VERSION "FL_CH_CANFD"

NS_ :

BS_:

BU_: ACU ADCC APA EGS EPS ESP FLZCU ONEBOX RXCU

BO_ 555 ONEBOX_3: 48 ESP
 SG_ ONEBOX_3_CRC1 : 7|8@0+ (1,0) [0|255] "" RXCU
 SG_ ONEBOX_3_RollgCntr1 : 11|4@0+ (1,0) [0|14] "" RXCU
 SG_ ONEBOX_3_Resd1 : 15|4@0+ (1,0) [0|15] "" RXCU
 SG_ ONEBOX_3_AVHSts : 17|2@0+ (1,0) [0|3] "" RXCU
 SG_ VehicleStandstill : 19|2@0+ (1,0) [0|3] "" RXCU
 SG_ NoBrakeForce : 22|1@0+ (1,0) [0|1] "" RXCU
 SG_ ONEBOX_3_AVHFailSts : 23|1@0+ (1,0) [0|1] "" RXCU
 SG_ Reserved_EDCActive : 24|1@0+ (1,0) [0|1] "" RXCU
 SG_ ECDTempOff : 25|1@0+ (1,0) [0|1] "" RXCU
 SG_ DCFail : 26|1@0+ (1,0) [0|1] "" RXCU
 SG_ CDDActive : 27|1@0+ (1,0) [0|1] "" RXCU
 SG_ CDDAvailable : 28|1@0+ (1,0) [0|1] "" RXCU
 SG_ Reserved_ESPLampInformation : 43|1@0+ (1,0) [0|1] "" RXCU
 SG_ TorqueMaxLimt : 55|8@0+ (16,0) [0|4064] "NM" RXCU
 SG_ ClutchOpenRequest : 57|2@0+ (1,0) [0|3] "" RXCU
 SG_ QDCACC : 63|2@0+ (1,0) [0|3] "" RXCU
 SG_ ONEBOX_3_CRC2 : 71|8@0+ (1,0) [0|255] "" RXCU
 SG_ ONEBOX_3_RollgCntr2 : 75|4@0+ (1,0) [0|14] "" RXCU
 SG_ ONEBOX_3_Resd2 : 79|4@0+ (1,0) [0|15] "" RXCU
 SG_ ONEBOX_3_WheelBrakeForce : 87|16@0+ (8,-250000) [-250000|250000] "N" RXCU
 SG_ TorqueIncreaseReqRA : 103|16@0+ (1,-32768) [-32768|32767] "NM" RXCU
 SG_ TorqueReductReqRA : 119|16@0+ (1,-32768) [-32768|32767] "NM" RXCU
 SG_ ONEBOX_3_CRC3 : 135|8@0+ (1,0) [0|255] "" RXCU
 SG_ ONEBOX_3_RollgCntr3 : 139|4@0+ (1,0) [0|14] "" RXCU
 SG_ ONEBOX_3_Resd3 : 143|4@0+ (1,0) [0|15] "" RXCU
 SG_ TorqueIncreaseReqFA : 151|16@0+ (1,-32768) [-32768|32767] "NM" RXCU
 SG_ TorqueReductReqFAFsat : 167|16@0+ (1,-32768) [-32768|32767] "NM" RXCU
 SG_ ONEBOX_3_CRC4 : 199|8@0+ (1,0) [0|255] "" RXCU
 SG_ ONEBOX_3_RollgCntr4 : 203|4@0+ (1,0) [0|14] "" RXCU
 SG_ ONEBOX_3_Resd4 : 207|4@0+ (1,0) [0|15] "" RXCU
 SG_ TorqueIncreaseReqRAValidData : 208|1@0+ (1,0) [0|1] "" RXCU
 SG_ TorqueReductReqRAValidData : 209|1@0+ (1,0) [0|1] "" RXCU
 SG_ TorqueIncreaseReqFAValidData : 210|1@0+ (1,0) [0|1] "" RXCU
 SG_ TorqueReductReqFAFastValidData : 211|1@0+ (1,0) [0|1] "" RXCU
 SG_ ESP_Park_CurrentSystemStatus : 215|3@0+ (1,0) [0|7] "" RXCU
 SG_ ESP_Pilot_CurrentSystemStatus : 218|3@0+ (1,0) [0|7] "" RXCU
 SG_ PlungerPressureValidData_22Bh : 220|1@0+ (1,0) [0|1] "" RXCU
 SG_ IPB_InputRodStrokeStatus_22Bh : 221|1@0+ (1,0) [0|1] "" RXCU
 SG_ SCMActive : 222|1@0+ (1,0) [0|1] "" RXCU
 SG_ SCMAvalable : 223|1@0+ (1,0) [0|1] "" RXCU
 SG_ IPB_PlungerPressure_22Bh : 231|10@0+ (1,0) [0|1022] "Bar" RXCU
 SG_ IPB_InputRodStroke_22Bh : 237|10@0+ (0.05,-5) [-5|46.15] "mm" RXCU
 SG_ BrakePedalPressStsValidData : 240|1@0+ (1,0) [0|1] "" RXCU
 SG_ DTCActive : 241|1@0+ (1,0) [0|1] "" RXCU
 SG_ DTCAvailable : 242|1@0+ (1,0) [0|1] "" RXCU
 SG_ DTC_Intervention : 243|1@0+ (1,0) [0|1] "" RXCU
 SG_ BrakePedalPressSts : 255|2@0+ (1,0) [0|3] "" RXCU
 SG_ ONEBOX_3_CRC5 : 263|8@0+ (1,0) [0|255] "" RXCU
 SG_ ONEBOX_3_RollgCntr5 : 267|4@0+ (1,0) [0|14] "" RXCU
 SG_ ONEBOX_3_Resd5 : 271|4@0+ (1,0) [0|15] "" RXCU
 SG_ ONEBOX_CRC6_22Bh : 327|8@0+ (1,0) [0|255] "" RXCU
 SG_ ONEBOX_RollgCntr6_22Bh : 331|4@0+ (1,0) [0|14] "" RXCU
 SG_ ONEBOX_Resd6_22Bh : 335|4@0+ (1,0) [0|15] "" RXCU

BO_ 571 FLZCU_1: 8 FLZCU
 SG_ DrvDoorSts_23Bh : 23|2@0+ (1,0) [0|3] "" RXCU
 SG_ DrvSeatBeltSW_23Bh : 31|1@0+ (1,0) [0|1] "" RXCU

BO_ 572 ONEBOX_7: 48 ESP
 SG_ ONEBOX_7_CRC1 : 7|8@0+ (1,0) [0|255] "" RXCU
 SG_ ONEBOX_7_RollgCntr1 : 11|4@0+ (1,0) [0|14] "" RXCU
 SG_ ONEBOX_7_Resd1 : 15|4@0+ (1,0) [0|15] "" RXCU
 SG_ ONEBOX_7_Crossaxis_TqtTrq : 23|16@0+ (1,-32768) [-32768|32767] "Nm" RXCU
 SG_ ONEBOX_7_iCCO_TqtTrq : 39|16@0+ (1,-32768) [-32768|32767] "Nm" RXCU
 SG_ ONEBOX_7_TAB_Active : 51|2@0+ (1,0) [0|3] "" RXCU
 SG_ ONEBOX_7_iTASDangerQuit : 52|1@0+ (1,0) [0|1] "" RXCU
 SG_ ONEBOX_7_RearWheelDirReq : 54|2@0+ (1,0) [0|3] "" RXCU
 SG_ ONEBOX_7_iTASAvailable : 55|1@0+ (1,0) [0|1] "" RXCU
 SG_ ONEBOX_7_iTASEnable : 56|1@0+ (1,0) [0|1] "" RXCU
 SG_ ONEBOX_7_iTASBMsr_FA : 57|1@0+ (1,0) [0|1] "" RXCU
 SG_ ONEBOX_7_iTASBMsr_RA : 58|1@0+ (1,0) [0|1] "" RXCU
 SG_ ONEBOX_7_BSW_Active : 60|2@0+ (1,0) [0|3] "" RXCU
 SG_ ONEBOX_7_iTASStuckDetected : 61|1@0+ (1,0) [0|1] "" RXCU
 SG_ ONEBOX_7_iTASTDiscHigh : 62|1@0+ (1,0) [0|1] "" RXCU
 SG_ ONEOBX_7_iTASAchMaxActTime : 63|1@0+ (1,0) [0|1] "" RXCU
 SG_ ONEBOX_7_CRC2 : 71|8@0+ (1,0) [0|255] "" RXCU
 SG_ ONEBOX_7_RollgCntr2 : 75|4@0+ (1,0) [0|14] "" RXCU
 SG_ ONEBOX_7_Resd2 : 79|4@0+ (1,0) [0|15] "" RXCU
 SG_ ONEBOX_7_iTASTorqueInc_FA : 87|16@0+ (1,-30000) [-30000|30000] "Nm" RXCU
 SG_ ONEBOX_7_DRIFTModeSts : 97|2@0+ (1,0) [0|3] "" RXCU
 SG_ ONEBOX_7_DrivingMod : 101|4@0+ (1,0) [0|15] "" RXCU
 SG_ ONEBOX_7_iTAS_Active : 103|2@0+ (1,0) [0|3] "" RXCU
 SG_ ONEBOX_7_ExpertESPSts : 105|2@0+ (1,0) [0|3] "" RXCU
 SG_ ONEBOX_7_Crossaxis_Active : 107|2@0+ (1,0) [0|3] "" RXCU
 SG_ ONEBOX_7_iCCO_Active : 109|2@0+ (1,0) [0|3] "" RXCU
 SG_ ONEBOX_7_Crossaxis_TqtTrqReqVD : 110|1@0+ (1,0) [0|1] "" RXCU
 SG_ ONEBOX_7_iCCO_TqtTrqReqVD : 111|1@0+ (1,0) [0|1] "" RXCU
 SG_ ONEBOX_7_iTASTorqueInc_RA : 119|16@0+ (1,-30000) [-30000|30000] "Nm" RXCU
 SG_ ONEBOX_7_iCCO_TgtVel : 151|8@0+ (0.1,0) [0|20] "" RXCU

BO_ 587 ONEBOX_4: 48 ESP
 SG_ ONEBOX_4_CRC1 : 7|8@0+ (1,0) [0|255] "" RXCU
 SG_ ONEBOX_4_RollgCntr1 : 11|4@0+ (1,0) [0|14] "" RXCU
 SG_ ONEBOX_4_Resd1 : 15|4@0+ (1,0) [0|15] "" RXCU
 SG_ ONEBOX_4_LHFWheelSpeedRPM : 23|16@0+ (0.0625,0) [0|4095.875] "rpm" RXCU
 SG_ ONEBOX_4_RHFWheelSpeedRPM : 39|16@0+ (0.0625,0) [0|4095.875] "rpm" RXCU
 SG_ ONEBOX_4_CRC2 : 71|8@0+ (1,0) [0|255] "" RXCU
 SG_ ONEBOX_4_RollgCntr2 : 75|4@0+ (1,0) [0|14] "" RXCU
 SG_ ONEBOX_4_Resd2 : 79|4@0+ (1,0) [0|15] "" RXCU
 SG_ LHRPulseCounter : 103|13@0+ (1,0) [0|8191] "pulse" RXCU
 SG_ LHRPulseCounterFailSts : 106|1@0+ (1,0) [0|1] "" RXCU
 SG_ RHRPulseCounter : 119|13@0+ (1,0) [0|8191] "pulse" RXCU
 SG_ RHRPulseCounterFailSts : 122|1@0+ (1,0) [0|1] "" RXCU
 SG_ ONEBOX_4_CRC3 : 135|8@0+ (1,0) [0|255] "" RXCU
 SG_ ONEBOX_4_RollgCntr3 : 139|4@0+ (1,0) [0|14] "" RXCU
 SG_ ONEBOX_4_Resd3 : 143|4@0+ (1,0) [0|15] "" RXCU
 SG_ RHFPulseCounter : 151|13@0+ (1,0) [0|8191] "pulse" RXCU
 SG_ RHFPulseCounterFailSts : 154|1@0+ (1,0) [0|1] "" RXCU
 SG_ LHFPulseCounter : 167|13@0+ (1,0) [0|8191] "pulse" RXCU
 SG_ LHFPulseCounterFailSts : 170|1@0+ (1,0) [0|1] "" RXCU
 SG_ LHFWheelSpeedRaw : 183|12@0+ (0.05,-30) [-30|80] "m/s" RXCU
 SG_ LHFWheelSpeedRawValidData : 184|1@0+ (1,0) [0|1] "" RXCU
 SG_ ONEBOX_4_CRC4 : 199|8@0+ (1,0) [0|255] "" RXCU
 SG_ ONEBOX_4_RollgCntr4 : 203|4@0+ (1,0) [0|14] "" RXCU
 SG_ ONEBOX_4_Resd4 : 207|4@0+ (1,0) [0|15] "" RXCU
 SG_ RHFWheelSpeedRaw : 215|12@0+ (0.05,-30) [-30|80] "m/s" RXCU
 SG_ RHFWheelSpeedRawValidData : 216|1@0+ (1,0) [0|1] "" RXCU
 SG_ LHRWheelSpeedRaw : 231|12@0+ (0.05,-30) [-30|80] "m/s" RXCU
 SG_ LHRWheelSpeedRawValidData : 232|1@0+ (1,0) [0|1] "" RXCU
 SG_ RHRWheelSpeedRaw : 247|12@0+ (0.05,-30) [-30|80] "m/s" RXCU
 SG_ RHRWheelSpeedRawValidData : 248|1@0+ (1,0) [0|1] "" RXCU
 SG_ ONEBOX_4_CRC5 : 263|8@0+ (1,0) [0|255] "" RXCU
 SG_ ONEBOX_4_RollgCntr5 : 267|4@0+ (1,0) [0|14] "" RXCU
 SG_ ONEBOX_4_Resd5 : 271|4@0+ (1,0) [0|15] "" RXCU
 SG_ ONEBOX_4_CRC6 : 327|8@0+ (1,0) [0|255] "" RXCU
 SG_ ONEBOX_4_RollgCntr6 : 331|4@0+ (1,0) [0|14] "" RXCU
 SG_ ONEBOX_4_Resd6 : 335|4@0+ (1,0) [0|15] "" RXCU

BO_ 612 EPB_R_1: 24 ESP
 SG_ CRC1_264h : 7|8@0+ (1,0) [0|255] "" RXCU
 SG_ RollgCntr1_264h : 11|4@0+ (1,0) [0|14] "" RXCU
 SG_ ActrSt_264h : 23|3@0+ (1,0) [0|7] "" RXCU
 SG_ RWUSt_264h : 25|1@0+ (1,0) [0|1] "" RXCU
 SG_ IPB_EPBErrorStatus : 41|1@0+ (1,0) [0|1] "" RXCU
 SG_ EPB_R_1_CRC2_264h : 71|8@0+ (1,0) [0|255] "" RXCU
 SG_ EPB_R_1_RollgCntr2_264h : 75|4@0+ (1,0) [0|14] "" RXCU
 SG_ EPB_R_1_Resd2_264h : 79|4@0+ (1,0) [0|15] "" RXCU
 SG_ EPB_R_1_CRC3_264h : 135|8@0+ (1,0) [0|255] "" RXCU
 SG_ EPB_R_1_RollgCntr3_264h : 139|4@0+ (1,0) [0|14] "" RXCU
 SG_ EPB_R_1_Resd3_264h : 143|4@0+ (1,0) [0|15] "" RXCU

BO_ 631 CSA_2: 8 EGS
 SG_ CSA_2_AllWarningInfo : 21|3@0+ (1,0) [0|7] "" RXCU

BO_ 788 ADS_COM_2: 8 ADCC
 SG_ HighVoltageReq_314h : 27|1@0+ (1,0) [0|1] "" RXCU

BO_ 794 ADS_COM_3: 24 FLZCU
 SG_ FCM_2_Weather_signal_31Ah : 51|2@0+ (1,0) [0|3] "" RXCU

BO_ 1041 ADS_HW_411h: 48 ADCC
 SG_ ADS_CRC1_411h : 7|8@0+ (1,0) [0|255] "" RXCU
 SG_ ADS_RollgCntr1_411h : 11|4@0+ (1,0) [0|14] "" RXCU
 SG_ ADS_Resd1_411h : 15|4@0+ (1,0) [0|15] "" RXCU
 SG_ ADS_RadarWarning0Distance_411h : 23|8@0+ (1,0) [0|255] "cm" RXCU
 SG_ ADS_RadarWarning1Distance_411h : 31|8@0+ (1,0) [0|255] "cm" RXCU
 SG_ ADS_RadarWarning2Distance_411h : 39|8@0+ (1,0) [0|255] "cm" RXCU
 SG_ ADS_RadarWarning3Distance_411h : 47|8@0+ (1,0) [0|255] "cm" RXCU
 SG_ ADS_RadarWarning4Distance_411h : 55|8@0+ (1,0) [0|255] "cm" RXCU
 SG_ ADS_RadarWarning5Distance_411h : 63|8@0+ (1,0) [0|255] "cm" RXCU
 SG_ ADS_CRC2_411h : 71|8@0+ (1,0) [0|255] "" RXCU
 SG_ ADS_RollgCntr2_411h : 75|4@0+ (1,0) [0|14] "" RXCU
 SG_ ADS_Resd2_411h : 79|4@0+ (1,0) [0|15] "" RXCU
 SG_ ADS_RadarWarning6Distance_411h : 87|8@0+ (1,0) [0|255] "cm" RXCU
 SG_ ADS_RadarWarning7Distance_411h : 95|8@0+ (1,0) [0|255] "cm" RXCU
 SG_ ADS_RadarWarning8Distance_411h : 103|8@0+ (1,0) [0|255] "cm" RXCU
 SG_ ADS_RadarWarning9Distance_411h : 111|8@0+ (1,0) [0|255] "cm" RXCU
 SG_ ADS_RadarWarning10Distance_411h : 119|8@0+ (1,0) [0|255] "cm" RXCU
 SG_ ADS_RadarWarning11Distance_411h : 127|8@0+ (1,0) [0|255] "cm" RXCU
 SG_ ADS_CRC3_411h : 135|8@0+ (1,0) [0|255] "" RXCU
 SG_ ADS_RollgCntr3_411h : 139|4@0+ (1,0) [0|14] "" RXCU
 SG_ ADS_Resd3_411h : 143|4@0+ (1,0) [0|15] "" RXCU
 SG_ ADS_RadarWarning12Distance_411h : 151|8@0+ (1,0) [0|255] "cm" RXCU
 SG_ ADS_RadarWarning13Distance_411h : 159|8@0+ (1,0) [0|255] "cm" RXCU
 SG_ ADS_RadarWarning14Distance_411h : 167|8@0+ (1,0) [0|255] "cm" RXCU
 SG_ ADS_RadarWarning15Distance_411h : 175|8@0+ (1,0) [0|255] "cm" RXCU
 SG_ ADS_RadarWarning2AcLvl_411h : 177|3@0+ (1,0) [0|7] "" RXCU
 SG_ ADS_RadarWarning1AcLvl_411h : 180|3@0+ (1,0) [0|7] "" RXCU
 SG_ ADS_RadarWarning0AcLvl_411h : 183|3@0+ (1,0) [0|7] "" RXCU
 SG_ ADS_RadarWarning4AcLvl_411h : 187|3@0+ (1,0) [0|7] "" RXCU
 SG_ ADS_RadarWarning3AcLvl_411h : 190|3@0+ (1,0) [0|7] "" RXCU
 SG_ ADS_CRC4_411h : 199|8@0+ (1,0) [0|255] "" RXCU
 SG_ ADS_RollgCntr4_411h : 203|4@0+ (1,0) [0|14] "" RXCU
 SG_ ADS_Resd4_411h : 207|4@0+ (1,0) [0|15] "" RXCU
 SG_ ADS_RadarWarning7AcLvl_411h : 209|3@0+ (1,0) [0|7] "" RXCU
 SG_ ADS_RadarWarning6AcLvl_411h : 212|3@0+ (1,0) [0|7] "" RXCU
 SG_ ADS_RadarWarning5AcLvl_411h : 215|3@0+ (1,0) [0|7] "" RXCU
 SG_ ADS_RadarWarning10AcLvl_411h : 216|3@0+ (1,0) [0|7] "" RXCU
 SG_ ADS_RadarWarning9AcLvl_411h : 219|3@0+ (1,0) [0|7] "" RXCU
 SG_ ADS_RadarWarning8AcLvl_411h : 222|3@0+ (1,0) [0|7] "" RXCU
 SG_ ADS_RadarWarning12AcLvl_411h : 226|3@0+ (1,0) [0|7] "" RXCU
 SG_ ADS_RadarWarning11AcLvl_411h : 229|3@0+ (1,0) [0|7] "" RXCU
 SG_ ADS_RadarWarning15AcLvl_411h : 233|3@0+ (1,0) [0|7] "" RXCU
 SG_ ADS_RadarWarning14AcLvl_411h : 236|3@0+ (1,0) [0|7] "" RXCU
 SG_ ADS_RadarWarning13AcLvl_411h : 239|3@0+ (1,0) [0|7] "" RXCU
 SG_ ADC_MdcSentryAlarmMod_411h : 244|1@0+ (1,0) [0|1] "" RXCU
 SG_ ADC_FuncReq_SentryModDetec_411h : 245|1@0+ (1,0) [0|1] "" RXCU
 SG_ ADC_FuncReq_SentryModWarn_411h : 246|1@0+ (1,0) [0|1] "" RXCU
 SG_ ADS_CRC5_411h : 263|8@0+ (1,0) [0|255] "" RXCU
 SG_ ADS_RollgCntr5_411h : 267|4@0+ (1,0) [0|14] "" RXCU
 SG_ ADS_Resd5_411h : 271|4@0+ (1,0) [0|15] "" RXCU
 SG_ ADS_CRC6_411h : 327|8@0+ (1,0) [0|255] "" RXCU
 SG_ ADS_RollgCntr6_411h : 331|4@0+ (1,0) [0|14] "" RXCU
 SG_ ADS_Resd6_411h : 335|4@0+ (1,0) [0|15] "" RXCU

BO_ 1042 ADS_HW_412h: 16 ADCC
 SG_ ADS_CRC1_412h : 7|8@0+ (1,0) [0|255] "" RXCU
 SG_ ADS_RollgCntr1_412h : 11|4@0+ (1,0) [0|14] "" RXCU
 SG_ ADS_Resd1_412h : 15|4@0+ (1,0) [0|15] "" RXCU
 SG_ ADS_MdcCrtSts_412h : 59|3@0+ (1,0) [0|7] "" RXCU
 SG_ ADS_CRC2_412h : 71|8@0+ (1,0) [0|255] "" RXCU
 SG_ ADS_RollgCntr2_412h : 75|4@0+ (1,0) [0|14] "" RXCU
 SG_ ADS_Resd2_412h : 79|4@0+ (1,0) [0|15] "" RXCU
 SG_ ADS_PwrOnOffReq_412h : 81|3@0+ (1,0) [0|7] "" RXCU
 SG_ ADS_ThmPostRun_412h : 86|1@0+ (1,0) [0|1] "" RXCU
 SG_ ADS_HVCtrlReq_412h : 87|1@0+ (1,0) [0|1] "" RXCU
 SG_ ADS_HiBeamReq_412h : 90|1@0+ (1,0) [0|1] "" RXCU
 SG_ ADS_HMAStatus_412h : 92|2@0+ (1,0) [0|3] "" RXCU
 SG_ ADS_hmaOnOffSts_412h : 94|2@0+ (1,0) [0|3] "" RXCU

BO_ 1193 ONEBOX_2_G: 8 ONEBOX
 SG_ IPB_System_Status : 60|3@0+ (1,0) [0|7] "" RXCU

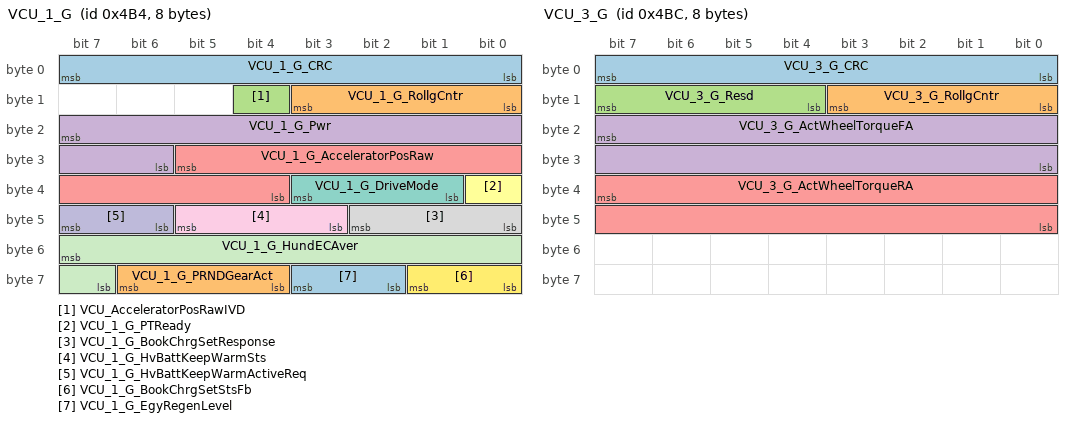
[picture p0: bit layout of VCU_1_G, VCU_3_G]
BO_ 1204 VCU_1_G: 8 RXCU
 SG_ VCU_1_G_CRC : 7|8@0+ (1,0) [0|255] "" ADCC,APA,ONEBOX
 SG_ VCU_1_G_RollgCntr : 11|4@0+ (1,0) [0|14] "" ADCC,APA,ONEBOX
 SG_ VCU_AcceleratorPosRawIVD : 12|1@0+ (1,0) [0|1] "" Vector__XXX
 SG_ VCU_1_G_Pwr : 23|10@0+ (1,-500) [-500|500] "" ADCC
 SG_ VCU_1_G_AcceleratorPosRaw : 29|10@0+ (0.1,0) [0|100] "%" ACU,ADCC,APA,EPS
 SG_ VCU_1_G_PTReady : 32|1@0+ (1,0) [0|1] "" ADCC,APA,EGS,EPS,ONEBOX
 SG_ VCU_1_G_DriveMode : 35|3@0+ (1,0) [0|7] "" APA,ONEBOX
 SG_ VCU_1_G_BookChrgSetResponse : 42|3@0+ (1,0) [0|7] "" Vector__XXX
 SG_ VCU_1_G_HvBattKeepWarmSts : 45|3@0+ (1,0) [0|7] "" Vector__XXX
 SG_ VCU_1_G_HvBattKeepWarmActiveReq : 47|2@0+ (1,0) [0|3] "" Vector__XXX
 SG_ VCU_1_G_HundECAver : 55|9@0+ (0.1,0) [0|51] "kwh" ADCC
 SG_ VCU_1_G_BookChrgSetStsFb : 57|2@0+ (1,0) [0|3] "" Vector__XXX
 SG_ VCU_1_G_EgyRegenLevel : 59|2@0+ (1,0) [0|3] "" ADCC
 SG_ VCU_1_G_PRNDGearAct : 62|3@0+ (1,0) [0|7] "" ACU,ADCC,EGS,EPS

BO_ 1209 VCU_2_G: 8 RXCU
 SG_ VCU_2_G_CRC : 7|8@0+ (1,0) [0|255] "" ADCC,APA,EPS
 SG_ VCU_2_G_RollgCntr : 11|4@0+ (1,0) [0|14] "" ADCC,APA,EPS
 SG_ VCU_2_G_Resd : 15|4@0+ (1,0) [0|15] "" ADCC,APA,EPS
 SG_ VCU_2_G_GasPedalPosInvalidData : 24|1@0+ (1,0) [0|1] "" ACU,ADCC,APA,EPS
 SG_ VCU_2_G_PowerLimit : 25|1@0+ (1,0) [0|1] "" ADCC
 SG_ VCU_2_G_BrakeLightReq : 26|1@0+ (1,0) [0|1] "" ADCC
 SG_ VCU_2_G_VehicleSystemFailure : 27|1@0+ (1,0) [0|1] "" ADCC
 SG_ OnekeyHVOffSuccess_4B9h : 28|1@0+ (1,0) [0|1] "" Vector__XXX
 SG_ VCU_2_G_BootloadSts : 29|1@0+ (1,0) [0|1] "" ADCC
 SG_ VCU_2_G_DischgSts : 30|1@0+ (1,0) [0|1] "" ADCC
 SG_ VCU_2_G_BrakePedalStsValidData : 31|1@0+ (1,0) [0|1] "" ACU,ADCC,EPS
 SG_ VCU_2_G_ExhibitionMod : 32|1@0+ (1,0) [0|1] "" APA
 SG_ VCU_2_G_BrakePedalSts : 36|1@0+ (1,0) [0|1] "" ACU,ADCC,EPS
 SG_ VCU_2_G_DCDCEnable : 37|1@0+ (1,0) [0|1] "" ADCC
 SG_ VCU_2_G_HVReady : 38|1@0+ (1,0) [0|1] "" ADCC,APA,EPS
 SG_ Res_VCU_2_G_Brake_state : 39|1@0+ (1,0) [0|1] "" ADCC
 SG_ VCU_2_G_VCUEnergyflow : 43|4@0+ (1,0) [0|15] "" ADCC
 SG_ VCU_2_G_GasPedalPosition : 49|10@0+ (0.1,0) [0|100] "%" ACU,ADCC,APA,EPS
 SG_ VCU_2_G_DrvGearShiftFailureIndcn : 53|4@0+ (1,0) [0|15] "" ADCC
 SG_ VCU_2_G_OnekeyHVoffStyle : 55|2@0+ (1,0) [0|3] "" Vector__XXX

BO_ 1212 VCU_3_G: 8 RXCU
 SG_ VCU_3_G_CRC : 7|8@0+ (1,0) [0|255] "" ADCC,FLZCU
 SG_ VCU_3_G_RollgCntr : 11|4@0+ (1,0) [0|14] "" ADCC,FLZCU
 SG_ VCU_3_G_Resd : 15|4@0+ (1,0) [0|15] "" ADCC,FLZCU
 SG_ VCU_3_G_ActWheelTorqueFA : 23|16@0+ (1,-32768) [-32768|32767] "NM" ADCC,FLZCU
 SG_ VCU_3_G_ActWheelTorqueRA : 39|16@0+ (1,-32768) [-32768|32767] "NM" ADCC,FLZCU

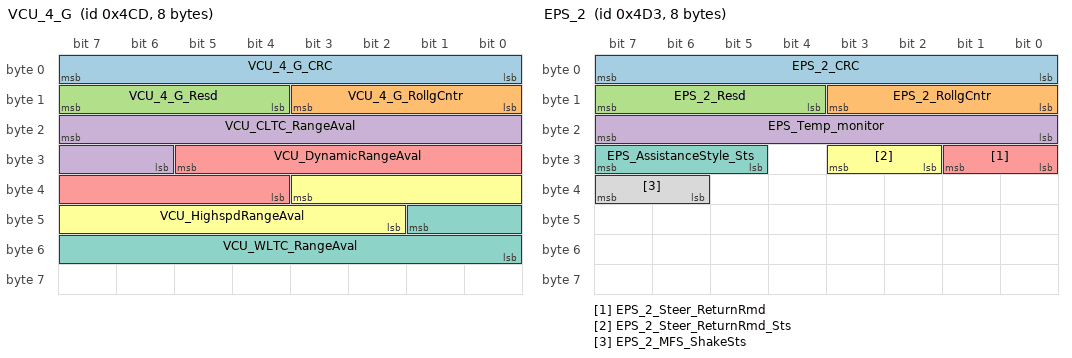
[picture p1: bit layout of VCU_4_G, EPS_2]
BO_ 1229 VCU_4_G: 8 RXCU
 SG_ VCU_4_G_CRC : 7|8@0+ (1,0) [0|255] "" ADCC,FLZCU
 SG_ VCU_4_G_RollgCntr : 11|4@0+ (1,0) [0|14] "" ADCC,FLZCU
 SG_ VCU_4_G_Resd : 15|4@0+ (1,0) [0|15] "" ADCC,FLZCU
 SG_ VCU_CLTC_RangeAval : 23|10@0+ (1,0) [0|1022] "KM" ADCC,FLZCU
 SG_ VCU_DynamicRangeAval : 29|10@0+ (1,0) [0|1022] "KM" ADCC,APA,FLZCU
 SG_ VCU_HighspdRangeAval : 35|10@0+ (1,0) [0|1022] "KM" ADCC,FLZCU
 SG_ VCU_WLTC_RangeAval : 41|10@0+ (1,0) [0|1022] "KM" ADCC,APA,FLZCU

BO_ 1235 EPS_2: 8 EPS
 SG_ EPS_2_CRC : 7|8@0+ (1,0) [0|255] "" RXCU
 SG_ EPS_2_RollgCntr : 11|4@0+ (1,0) [0|14] "" RXCU
 SG_ EPS_2_Resd : 15|4@0+ (1,0) [0|15] "" RXCU
 SG_ EPS_Temp_monitor : 23|8@0+ (1,-70) [-70|184] "℃" RXCU
 SG_ EPS_2_Steer_ReturnRmd : 25|2@0+ (1,0) [0|3] "" RXCU
 SG_ EPS_2_Steer_ReturnRmd_Sts : 27|2@0+ (1,0) [0|3] "" RXCU
 SG_ EPS_AssistanceStyle_Sts : 31|3@0+ (1,0) [0|7] "" RXCU
 SG_ EPS_2_MFS_ShakeSts : 39|2@0+ (1,0) [0|3] "" RXCU

BO_ 1314 HCU_25: 64 RXCU
 SG_ HCU_CRC1_522h : 7|8@0+ (1,0) [0|255] "" ADCC
 SG_ HCU_RollgCntr1_522h : 11|4@0+ (1,0) [0|14] "" ADCC
 SG_ HCU_Resd1_522h : 15|4@0+ (1,0) [0|15] "" ADCC
 SG_ HCU_V2lDisChgBck : 17|2@0+ (1,0) [0|3] "" Vector__XXX
 SG_ HCU_DisChgMemFed : 19|2@0+ (1,0) [0|3] "" Vector__XXX
 SG_ HCU_V2VDisChgBck : 21|2@0+ (1,0) [0|3] "" Vector__XXX
 SG_ HCU_V2l_IntlDisChgBck : 23|2@0+ (1,0) [0|3] "" Vector__XXX
 SG_ HCU_FuelDetnOpDefeated : 25|2@0+ (1,0) [0|3] "" Vector__XXX
 SG_ HCU_FuelDetnModSwtFed : 27|2@0+ (1,0) [0|3] "" Vector__XXX
 SG_ HCU_FuelDetnStateFed : 29|2@0+ (1,0) [0|3] "" Vector__XXX
 SG_ HCU_HVDownRepairModeFed : 31|2@0+ (1,0) [0|3] "" Vector__XXX
 SG_ HCU_SumFuCns : 37|9@0+ (0.1,0) [0|50] "L/km" Vector__XXX
 SG_ HCU_TrailerMode : 39|2@0+ (1,0) [0|3] "" Vector__XXX
 SG_ HCU_TABSwtFed_522h : 40|2@0+ (1,0) [0|3] "" Vector__XXX
 SG_ HCU_MotSelfHeatLvlReq : 43|3@0+ (1,0) [0|7] "" Vector__XXX
 SG_ HCU_MotSelfHeatEnReq : 44|1@0+ (1,0) [0|1] "" Vector__XXX
 SG_ HCU_KeyDriveModememory : 49|2@0+ (1,0) [0|3] "" Vector__XXX
 SG_ HCU_DrivePowerDispSetFed : 51|2@0+ (1,0) [0|3] "" Vector__XXX
 SG_ HCU_TCMStsReq_522h : 54|1@0+ (1,0) [0|1] "" Vector__XXX
 SG_ HCU_EXPERTNormFed : 57|2@0+ (1,0) [0|3] "" Vector__XXX
 SG_ HCU_4LModeFed : 58|1@0+ (1,0) [0|1] "" ADCC,ONEBOX
 SG_ HCU_EXPERTEcoFed : 60|2@0+ (1,0) [0|3] "" Vector__XXX
 SG_ HCU_SingleRegnRmn : 61|1@0+ (1,0) [0|1] "" Vector__XXX
 SG_ HCU_DRIFTModeSts : 63|2@0+ (1,0) [0|3] "" ONEBOX
 SG_ HCU_CRC2_522h : 71|8@0+ (1,0) [0|255] "" ADCC
 SG_ HCU_RollgCntr2_522h : 75|4@0+ (1,0) [0|14] "" ADCC
 SG_ HCU_Resd2_522h : 79|4@0+ (1,0) [0|15] "" ADCC
 SG_ HCU_EXPERTAWDFed : 81|2@0+ (1,0) [0|3] "" Vector__XXX
 SG_ HCU_EXPERTRWDFed : 83|2@0+ (1,0) [0|3] "" Vector__XXX
 SG_ HCU_CrossaxisFed : 85|2@0+ (1,0) [0|3] "" ONEBOX
 SG_ HCU_EXPERTSportFed : 87|2@0+ (1,0) [0|3] "" Vector__XXX
 SG_ HCU_StopChrgnModeFed : 89|2@0+ (1,0) [0|3] "" Vector__XXX
 SG_ HCU_StopChrgnFed : 91|2@0+ (1,0) [0|3] "" Vector__XXX
 SG_ HCU_CLIMBFed : 93|2@0+ (1,0) [0|3] "" ADCC
 SG_ HCU_EXPERTAutoFed : 95|2@0+ (1,0) [0|3] "" Vector__XXX
 SG_ HCU_HEV_FunctionLimit : 96|1@0+ (1,0) [0|1] "" Vector__XXX
 SG_ HCU_ParkingChargeReminder : 97|1@0+ (1,0) [0|1] "" Vector__XXX
 SG_ HCU_PowerCut : 98|1@0+ (1,0) [0|1] "" Vector__XXX
 SG_ HCU_IMMOReleaseSignal : 99|1@0+ (1,0) [0|1] "" Vector__XXX
 SG_ HCU_LVPowSupSYSAbn_lit : 100|1@0+ (1,0) [0|1] "" Vector__XXX
 SG_ HCU_ChrgnFctMemSt : 102|2@0+ (1,0) [0|3] "" Vector__XXX
 SG_ HCU_PowerModeChangeInhibit : 104|1@0+ (1,0) [0|1] "" Vector__XXX
 SG_ HCU_DisconnectChagWarn : 105|1@0+ (1,0) [0|1] "" Vector__XXX
 SG_ HCU_EngineRunClmReq : 106|1@0+ (1,0) [0|1] "" Vector__XXX
 SG_ HCU_VehicleSpeedMax_Limit : 107|1@0+ (1,0) [0|1] "" Vector__XXX
 SG_ HCU_AccleAbility_Limit : 108|1@0+ (1,0) [0|1] "" Vector__XXX
 SG_ HCU_DriveInhibit_GearP : 109|1@0+ (1,0) [0|1] "" Vector__XXX
 SG_ HCU_SetModeNotChange : 110|1@0+ (1,0) [0|1] "" Vector__XXX
 SG_ HCU_UTURNSnowFed : 111|1@0+ (1,0) [0|1] "" Vector__XXX
 SG_ HCU_PowerLevel : 114|3@0+ (1,0) [0|7] "" Vector__XXX
 SG_ HCU_TowingModeEna : 115|1@0+ (1,0) [0|1] "" Vector__XXX
 SG_ HCU_LeaveVehicleWarning : 116|1@0+ (1,0) [0|1] "" Vector__XXX
 SG_ HCU_DedicatedModeInhibit : 117|1@0+ (1,0) [0|1] "" Vector__XXX
 SG_ HCU_DisChargeStopFault : 119|2@0+ (1,0) [0|3] "" Vector__XXX
 SG_ HCU_RearEDLSts : 123|4@0+ (1,0) [0|15] "" ONEBOX
 SG_ HCU_FrntEDLSts : 127|4@0+ (1,0) [0|15] "" ONEBOX
 SG_ HCU_CRC3_522h : 135|8@0+ (1,0) [0|255] "" ADCC
 SG_ HCU_RollgCntr3_522h : 139|4@0+ (1,0) [0|14] "" ADCC
 SG_ HCU_Resd3_522h : 143|4@0+ (1,0) [0|15] "" ADCC
 SG_ HCU_CruiseLimitSpeedValue : 146|13@0+ (0.0625,0) [0|511.875] "km/h" Vector__XXX
 SG_ HCU_DriveMode_JT : 151|5@0+ (1,0) [0|31] "" ADCC,EPS,ONEBOX
 SG_ HCU_SocManageFed : 162|3@0+ (1,0) [0|7] "" Vector__XXX
 SG_ HCU_SinglePedalMemFed : 163|1@0+ (1,0) [0|1] "" Vector__XXX
 SG_ HCU_CCOSwtFed : 165|2@0+ (1,0) [0|3] "" ADCC,ONEBOX
 SG_ HCU_Pwr : 175|12@0+ (1,-2000) [-2000|2000] "KW" Vector__XXX
 SG_ HCU_DrvGearShiftFailureIndcn : 179|4@0+ (1,0) [0|15] "" Vector__XXX
 SG_ HCU_UTURNSandFed : 184|1@0+ (1,0) [0|1] "" Vector__XXX
 SG_ HCU_CruiseControlStatus : 186|2@0+ (1,0) [0|3] "" ACU
 SG_ HCU_EXPERTEESPSet : 188|2@0+ (1,0) [0|3] "" ONEBOX
 SG_ HCU_EgyRegenLevel : 191|3@0+ (1,0) [0|7] "" Vector__XXX
 SG_ HCU_CRC4_522h : 199|8@0+ (1,0) [0|255] "" ADCC
 SG_ HCU_RollgCntr4_522h : 203|4@0+ (1,0) [0|14] "" ADCC
 SG_ HCU_Resd4_522h : 207|4@0+ (1,0) [0|15] "" ADCC
 SG_ HCU_EngyFlowToDisp : 211|5@0+ (1,0) [0|31] "" ONEBOX
 SG_ HCU_UTURNGrassFed : 212|1@0+ (1,0) [0|1] "" Vector__XXX
 SG_ HCU_UTURNMudFed : 213|1@0+ (1,0) [0|1] "" Vector__XXX
 SG_ HCU_LTCDispFed : 215|2@0+ (1,0) [0|3] "" Vector__XXX
 SG_ HCU_iTAS_Warn : 217|3@0+ (1,0) [0|7] "" Vector__XXX
 SG_ HCU_iCCO_Warn : 221|4@0+ (1,0) [0|15] "" Vector__XXX
 SG_ HCU_DriveModeChangeFail : 222|1@0+ (1,0) [0|1] "" Vector__XXX
 SG_ HCU_25_Crossaxis_Warn : 225|3@0+ (1,0) [0|7] "" Vector__XXX
 SG_ HCU_25_EDLFed : 227|2@0+ (1,0) [0|3] "" Vector__XXX
 SG_ HCU_DraggingModeRemind : 230|3@0+ (1,0) [0|7] "" Vector__XXX
 SG_ HCU_iTASSceneReq : 232|3@0+ (1,0) [0|7] "" ONEBOX
 SG_ HCU_25_iTAS_SlopWarn : 234|2@0+ (1,0) [0|3] "" Vector__XXX
 SG_ HCU_ExterTempLowHint : 236|2@0+ (1,0) [0|3] "" Vector__XXX
 SG_ HCU_iTAS_Active : 238|2@0+ (1,0) [0|3] "" Vector__XXX
 SG_ HCU_25_VehSpdOffroadRmn : 240|1@0+ (1,0) [0|1] "" Vector__XXX
 SG_ HCU_DrivingModReq : 245|5@0+ (1,0) [0|31] "" ONEBOX
 SG_ HCU_25_ADS_FctSts : 248|1@0+ (1,0) [0|1] "" Vector__XXX
 SG_ HCU_25_DRIFTModeSetReq : 251|3@0+ (1,0) [0|7] "" ONEBOX
 SG_ HCU_25_CrossaxisReq : 253|2@0+ (1,0) [0|3] "" ONEBOX
 SG_ HCU_25_CCOSwtReq : 255|2@0+ (1,0) [0|3] "" ONEBOX
 SG_ HCU_CRC5_522h : 263|8@0+ (1,0) [0|255] "" ADCC
 SG_ HCU_RollgCntr5_522h : 267|4@0+ (1,0) [0|14] "" ADCC
 SG_ HCU_Resd5_522h : 271|4@0+ (1,0) [0|15] "" ADCC
 SG_ HCU_25_ErrorCode : 279|16@0+ (1,0) [0|65535] "" Vector__XXX
 SG_ HCU_25_ErrorCount : 295|8@0+ (1,0) [0|255] "" Vector__XXX
 SG_ HCU_25_iDRIFT_Warn : 298|3@0+ (1,0) [0|7] "" Vector__XXX
 SG_ HCU_25_SetVehSpdOffroad : 300|2@0+ (1,0) [0|3] "" Vector__XXX
 SG_ HCU_25_LaunchMod_Warn : 303|3@0+ (1,0) [0|7] "" Vector__XXX
 SG_ HCU_25_TAB_Warn : 307|3@0+ (1,0) [0|7] "" Vector__XXX
 SG_ HCU_25_CCO_TextDisp : 311|4@0+ (1,0) [0|15] "" Vector__XXX
 SG_ HCU_25_DCM_Warn : 315|4@0+ (1,0) [0|15] "" Vector__XXX
 SG_ HCU_25_CCMFed : 317|2@0+ (1,0) [0|3] "" Vector__XXX
 SG_ HCU_25_TABReq : 319|2@0+ (1,0) [0|3] "" ADCC,ONEBOX
 SG_ HCU_SumElecCns : 339|12@0+ (0.1,-100) [-100|100] "kwh/100km" Vector__XXX
 SG_ HCU_CrossBorderSts : 341|2@0+ (1,0) [0|3] "" Vector__XXX
 SG_ HCU_DischgSetSOCFed : 367|8@0+ (1,0) [0|100] "%" Vector__XXX
 SG_ HCU_facCleverDrvAct_522h : 369|5@0+ (0.1,-1) [-1|2.1] "" Vector__XXX
 SG_ HCU_stCleverDrvAct_522h : 371|2@0+ (1,0) [0|3] "" Vector__XXX
 SG_ HCU_stCleverRgnAct_522h : 373|2@0+ (1,0) [0|3] "" Vector__XXX
 SG_ HCU_stCleverMainAct_522h : 375|2@0+ (1,0) [0|3] "" Vector__XXX
 SG_ EnergySavingModeSts_522h : 378|2@0+ (1,0) [0|3] "" Vector__XXX
 SG_ HCU_facCleverDrvActRstFed_522h : 380|2@0+ (1,0) [0|3] "" Vector__XXX
 SG_ HCU_SailramainingT_Indc_522h : 407|16@0+ (1,0) [0|65535] "s" Vector__XXX
 SG_ HCU_ATCM_Operation_REQ_522h : 416|3@0+ (1,0) [0|7] "" Vector__XXX
 SG_ HCU_ModeSwFailureIndc_522h : 419|3@0+ (1,0) [0|7] "" Vector__XXX
 SG_ HCU_Sailmode_522h : 423|4@0+ (1,0) [0|15] "" Vector__XXX
 SG_ HCU_CarSickRelfModeFb : 425|2@0+ (1,0) [0|3] "" ONEBOX
 SG_ HCU_DeepSnowSts_522h : 427|2@0+ (1,0) [0|3] "" Vector__XXX
 SG_ DriveModeChangeFailReason_522h : 429|2@0+ (1,0) [0|3] "" Vector__XXX
 SG_ HCU_CLIMBDisReason_522h : 433|4@0+ (1,0) [0|15] "" Vector__XXX
 SG_ HCU_CarSickRelfModeDisReason : 436|3@0+ (1,0) [0|7] "" Vector__XXX
 SG_ HCU_DCMSwtFed : 439|3@0+ (1,0) [0|7] "" Vector__XXX
 SG_ HCU_LightSandSts_522h : 445|2@0+ (1,0) [0|3] "" Vector__XXX

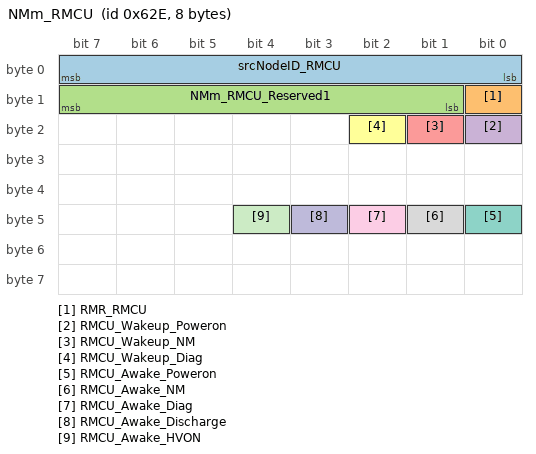
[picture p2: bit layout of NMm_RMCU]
BO_ 1582 NMm_RMCU: 8 RXCU
 SG_ srcNodeID_RMCU : 7|8@0+ (1,0) [0|255] "" Vector__XXX
 SG_ RMR_RMCU : 8|1@0+ (1,0) [0|1] "" Vector__XXX
 SG_ NMm_RMCU_Reserved1 : 15|7@0+ (1,0) [0|127] "" Vector__XXX
 SG_ RMCU_Wakeup_Poweron : 16|1@0+ (1,0) [0|1] "" Vector__XXX
 SG_ RMCU_Wakeup_NM : 17|1@0+ (1,0) [0|1] "" Vector__XXX
 SG_ RMCU_Wakeup_Diag : 18|1@0+ (1,0) [0|1] "" Vector__XXX
 SG_ RMCU_Awake_Poweron : 40|1@0+ (1,0) [0|1] "" Vector__XXX
 SG_ RMCU_Awake_NM : 41|1@0+ (1,0) [0|1] "" Vector__XXX
 SG_ RMCU_Awake_Diag : 42|1@0+ (1,0) [0|1] "" Vector__XXX
 SG_ RMCU_Awake_Discharge : 43|1@0+ (1,0) [0|1] "" Vector__XXX
 SG_ RMCU_Awake_HVON : 44|1@0+ (1,0) [0|1] "" Vector__XXX

BO_TX_BU_ 555 : ESP,ONEBOX;
BO_TX_BU_ 572 : ESP,ONEBOX;
BO_TX_BU_ 587 : ESP,ONEBOX;
BO_TX_BU_ 612 : ESP,ONEBOX;
BO_TX_BU_ 788 : ADCC,FLZCU;
CM_ BO_ 1041 "华为MDC新增";
CM_ BO_ 1042 "华为MDC新增";
CM_ SG_ 555 ONEBOX_3_CRC1 "Profile1A:E2E CRC (SAE J1850 CRC-8) for 8 Bytes
DataID:0x004D";
CM_ SG_ 555 ONEBOX_3_RollgCntr1 "Profile1A:E2E Rolling message counter(the maximum value of Alive counter is 14)";
CM_ SG_ 555 ONEBOX_3_Resd1 "Profile1A:E2E Reserved";
CM_ SG_ 555 ONEBOX_3_AVHSts "Auto Hold Functional state";
CM_ SG_ 555 VehicleStandstill "车辆静止状态
Stationary state of vehicle";
CM_ SG_ 555 NoBrakeForce "制动力存在性
No brake pressure applied
Generally it regards wheel cylinder pressure";
CM_ SG_ 555 ONEBOX_3_AVHFailSts "AutoHold Functional failure state";
CM_ SG_ 555 ECDTempOff "制动盘过温状态
Brake disc temperature is too high";
CM_ SG_ 555 DCFail "Notify the FRM when ACC's deceleration function cannot be performed";
CM_ SG_ 555 CDDActive "CDD Active";
CM_ SG_ 555 CDDAvailable "CDD Available";
CM_ SG_ 555 TorqueMaxLimt "当ClutchOpenRequest发00、01、11时，此信号发送默认值0xFE； 当ClutchOpenRequest发10时，TMM接收此限值，并控制其输出的扭矩值低于此限值；";
CM_ SG_ 555 ClutchOpenRequest "00：该请求无效
01：收到该值后，TMM会open clutch
10：收到该值后，TMM会去查询torque max limit，并使TMM输出扭矩小于该值。
11：该请求错误";
CM_ SG_ 555 QDCACC "ACC error detected by ESP, like timeout or alivecounter error.
The error should distinguish reversible and irreversible errors.";
CM_ SG_ 555 ONEBOX_3_CRC2 "Profile1A:E2E CRC (SAE J1850 CRC-8) for 8 Bytes
DataID:0x004E";
CM_ SG_ 555 ONEBOX_3_RollgCntr2 "Profile1A:E2E Rolling message counter(the maximum value of Alive counter is 14)";
CM_ SG_ 555 ONEBOX_3_Resd2 "Profile1A:E2E Reserved";
CM_ SG_ 555 ONEBOX_3_WheelBrakeForce "轮端制动力
Four-wheel total braking force
0xF425~0xFFFE：Not Used";
CM_ SG_ 555 TorqueIncreaseReqRA "RA:Rear axle
PHEV 上ONEBOX对HCU进行后轴升扭的请求";
CM_ SG_ 555 TorqueReductReqRA "RA:Rear axle
PHEV 上ONEBOX对HCU进行后轴降扭的请求";
CM_ SG_ 555 ONEBOX_3_CRC3 "Profile1A:E2E CRC (SAE J1850 CRC-8) for 8 Bytes
DataID:0x004F";
CM_ SG_ 555 ONEBOX_3_RollgCntr3 "Profile1A:E2E Rolling message counter(the maximum value of Alive counter is 14)";
CM_ SG_ 555 ONEBOX_3_Resd3 "Profile1A:E2E Reserved";
CM_ SG_ 555 TorqueIncreaseReqFA "FA:Front axle
PHEV 上ONEBOX对HCU进行前轴升扭的请求";
CM_ SG_ 555 TorqueReductReqFAFsat "FA:Front axle
PHEV 上ONEBOX对HCU进行前轴快降扭的请求";
CM_ SG_ 555 ONEBOX_3_CRC4 "Profile1A:E2E CRC (SAE J1850 CRC-8) for 8 Bytes
DataID:0x0050";
CM_ SG_ 555 ONEBOX_3_RollgCntr4 "Profile1A:E2E Rolling message counter(the maximum value of Alive counter is 14)";
CM_ SG_ 555 ONEBOX_3_Resd4 "Profile1A:E2E Reserved";
CM_ SG_ 555 ESP_Park_CurrentSystemStatus "ESP与ADS泊车控制握手信号";
CM_ SG_ 555 ESP_Pilot_CurrentSystemStatus "ESP与ADS行车控制握手信号";
CM_ SG_ 555 PlungerPressureValidData_22Bh "主缸压力有效性
Valid check bit of the signal PressureMasterCylinder";
CM_ SG_ 555 IPB_InputRodStrokeStatus_22Bh "踏板杆行程状态有效性Indicate inputRod stroke for pedal travel";
CM_ SG_ 555 SCMActive "Indicate SCM active or not";
CM_ SG_ 555 SCMAvalable "Indicate SCM available or not";
CM_ SG_ 555 IPB_PlungerPressure_22Bh "主缸压力
Pressure Master Cylinder";
CM_ SG_ 555 IPB_InputRodStroke_22Bh "踏板杆行程
Indicate inputRod stroke for pedal travel";
CM_ SG_ 555 BrakePedalPressStsValidData "刹车踏板有效信号
取消制动踏板硬开关新增";
CM_ SG_ 555 DTCActive "DTC function active";
CM_ SG_ 555 DTCAvailable "DTC function available";
CM_ SG_ 555 DTC_Intervention "DTC function of One Box, actived when the gas pedal was released so quick that the coast regen wasn't acive.";
CM_ SG_ 555 BrakePedalPressSts "刹车踏板状态信号   
取消制动踏板硬开关新增";
CM_ SG_ 555 ONEBOX_3_CRC5 "Profile1A:E2E CRC (SAE J1850 CRC-8) for 8 Bytes
DataID:0x01C9";
CM_ SG_ 555 ONEBOX_3_RollgCntr5 "Profile1A:E2E Rolling message counter(the maximum value of Alive counter is 14)";
CM_ SG_ 555 ONEBOX_3_Resd5 "Profile1A:E2E Reserved";
CM_ SG_ 555 ONEBOX_CRC6_22Bh "Profile1A:E2E CRC (SAE J1850 CRC-8) for 8 Bytes
DataID:0x01C8";
CM_ SG_ 555 ONEBOX_RollgCntr6_22Bh "Profile1A:E2E Rolling message counter(the maximum value of Alive counter is 14)";
CM_ SG_ 555 ONEBOX_Resd6_22Bh "Profile1A:E2E Reserved";
CM_ SG_ 571 DrvDoorSts_23Bh "主驾门状态";
CM_ SG_ 571 DrvSeatBeltSW_23Bh "安全带检测开关，0为未插入，1为插入";
CM_ SG_ 572 ONEBOX_7_CRC1 "Profile1A:E2E CRC (SAE J1850 CRC-8) for 8 Bytes
DataID:0x0115";
CM_ SG_ 572 ONEBOX_7_RollgCntr1 "Profile1A:E2E Rolling message counter(the maximum value of Alive counter is 14)";
CM_ SG_ 572 ONEBOX_7_Resd1 "Profile1A:E2E Reserved";
CM_ SG_ 572 ONEBOX_7_Crossaxis_TqtTrq "交叉轴模式IPB请求扭矩";
CM_ SG_ 572 ONEBOX_7_iCCO_TqtTrq "iCCO功能IPB请求扭矩";
CM_ SG_ 572 ONEBOX_7_TAB_Active "IPB反馈TAB状态";
CM_ SG_ 572 ONEBOX_7_iTASDangerQuit "iTAS功能使用车速过高提示";
CM_ SG_ 572 ONEBOX_7_RearWheelDirReq "后轴扭矩方向";
CM_ SG_ 572 ONEBOX_7_iTASAvailable "iTAS功能是否可用";
CM_ SG_ 572 ONEBOX_7_iTASEnable "iTAS功能是否启用";
CM_ SG_ 572 ONEBOX_7_iTASBMsr_FA "iTAS功能前轴请求目标扭矩标志位";
CM_ SG_ 572 ONEBOX_7_iTASBMsr_RA "iTAS功能后轴请求目标扭矩标志位";
CM_ SG_ 572 ONEBOX_7_BSW_Active "智能擦盘状态反馈信号";
CM_ SG_ 572 ONEBOX_7_iTASStuckDetected "iTAS功能激活后车辆是否被卡住";
CM_ SG_ 572 ONEBOX_7_iTASTDiscHigh "iTAS功能激活后刹车片温度是否过高";
CM_ SG_ 572 ONEOBX_7_iTASAchMaxActTime "是否达到iTAS功能使用最大时间";
CM_ SG_ 572 ONEBOX_7_CRC2 "Profile1A:E2E CRC (SAE J1850 CRC-8) for 8 Bytes
DataID:0x0116";
CM_ SG_ 572 ONEBOX_7_RollgCntr2 "Profile1A:E2E Rolling message counter(the maximum value of Alive counter is 14)";
CM_ SG_ 572 ONEBOX_7_Resd2 "Profile1A:E2E Reserved";
CM_ SG_ 572 ONEBOX_7_iTASTorqueInc_FA "iTAS功能前轴请求目标扭矩";
CM_ SG_ 572 ONEBOX_7_DRIFTModeSts "漂移模式IPB不同状态";
CM_ SG_ 572 ONEBOX_7_DrivingMod "IPB响应驾驶模式";
CM_ SG_ 572 ONEBOX_7_iTAS_Active "iTAS功能状态";
CM_ SG_ 572 ONEBOX_7_ExpertESPSts "IPB响应HCU发送专家模式ESP状态反馈";
CM_ SG_ 572 ONEBOX_7_Crossaxis_Active "IPB反馈交叉轴模式状态";
CM_ SG_ 572 ONEBOX_7_iCCO_Active "IPB反馈iCCO功能状态";
CM_ SG_ 572 ONEBOX_7_Crossaxis_TqtTrqReqVD "交叉轴模式IPB请求扭矩有效位";
CM_ SG_ 572 ONEBOX_7_iCCO_TqtTrqReqVD "iCCO功能IPB请求扭矩有效位";
CM_ SG_ 572 ONEBOX_7_iTASTorqueInc_RA "iTAS功能后轴请求目标扭矩";
CM_ SG_ 572 ONEBOX_7_iCCO_TgtVel "iCCO功能目标车速";
CM_ SG_ 587 ONEBOX_4_CRC1 "Profile1A:E2E CRC (SAE J1850 CRC-8) for 8 Bytes
DataID:0x0051";
CM_ SG_ 587 ONEBOX_4_RollgCntr1 "Profile1A:E2E Rolling message counter(the maximum value of Alive counter is 14)";
CM_ SG_ 587 ONEBOX_4_Resd1 "Profile1A:E2E Reserved";
CM_ SG_ 587 ONEBOX_4_LHFWheelSpeedRPM "left front Wheel Speed(the unit is RPM)";
CM_ SG_ 587 ONEBOX_4_RHFWheelSpeedRPM "right front  Wheel Speed(the unit is RPM)";
CM_ SG_ 587 ONEBOX_4_CRC2 "Profile1A:E2E CRC (SAE J1850 CRC-8) for 8 Bytes
DataID:0x0052";
CM_ SG_ 587 ONEBOX_4_RollgCntr2 "Profile1A:E2E Rolling message counter(the maximum value of Alive counter is 14)";
CM_ SG_ 587 ONEBOX_4_Resd2 "Profile1A:E2E Reserved";
CM_ SG_ 587 LHRPulseCounter "left rear wheel Pulse Counter";
CM_ SG_ 587 LHRPulseCounterFailSts "left rear wheel Pulse Counter Fail Status";
CM_ SG_ 587 RHRPulseCounter "right rear wheel Pulse Counter";
CM_ SG_ 587 RHRPulseCounterFailSts "right rear wheel Pulse Counter FailSts";
CM_ SG_ 587 ONEBOX_4_CRC3 "Profile1A:E2E CRC (SAE J1850 CRC-8) for 8 Bytes
DataID:0x0053";
CM_ SG_ 587 ONEBOX_4_RollgCntr3 "Profile1A:E2E Rolling message counter(the maximum value of Alive counter is 14)";
CM_ SG_ 587 ONEBOX_4_Resd3 "Profile1A:E2E Reserved";
CM_ SG_ 587 RHFPulseCounter "right front wheel Pulse Counter";
CM_ SG_ 587 RHFPulseCounterFailSts "right front wheel Pulse Counter FailSts";
CM_ SG_ 587 LHFPulseCounter "left front wheel Pulse Counter";
CM_ SG_ 587 LHFPulseCounterFailSts "left front wheel Pulse Counter FailSts";
CM_ SG_ 587 LHFWheelSpeedRaw "raw left front Wheel Speed";
CM_ SG_ 587 LHFWheelSpeedRawValidData "Valid check bit of the signal LHFWheelSpeedRaw";
CM_ SG_ 587 ONEBOX_4_CRC4 "Profile1A:E2E CRC (SAE J1850 CRC-8) for 8 Bytes
DataID:0x0054";
CM_ SG_ 587 ONEBOX_4_RollgCntr4 "Profile1A:E2E Rolling message counter(the maximum value of Alive counter is 14)";
CM_ SG_ 587 ONEBOX_4_Resd4 "Profile1A:E2E Reserved";
CM_ SG_ 587 RHFWheelSpeedRaw "raw right front Wheel Speed";
CM_ SG_ 587 RHFWheelSpeedRawValidData "Valid check bit of the signal RHFWheelSpeedRaw";
CM_ SG_ 587 LHRWheelSpeedRaw "raw left rear Wheel Speed";
CM_ SG_ 587 LHRWheelSpeedRawValidData "Valid check bit of the signal LHRWheelSpeedRaw";
CM_ SG_ 587 RHRWheelSpeedRaw "raw right rear Wheel Speed";
CM_ SG_ 587 RHRWheelSpeedRawValidData "Valid check bit of the signal RHRWheelSpeedRaw";
CM_ SG_ 587 ONEBOX_4_CRC5 "Profile1A:E2E CRC (SAE J1850 CRC-8) for 8 Bytes
DataID:0x00FD";
CM_ SG_ 587 ONEBOX_4_RollgCntr5 "Profile1A:E2E Rolling message counter(the maximum value of Alive counter is 14)";
CM_ SG_ 587 ONEBOX_4_Resd5 "Profile1A:E2E Reserved";
CM_ SG_ 587 ONEBOX_4_CRC6 "Profile1A:E2E CRC (SAE J1850 CRC-8) for 8 Bytes
DataID:0x00FE";
CM_ SG_ 587 ONEBOX_4_RollgCntr6 "Profile1A:E2E Rolling message counter(the maximum value of Alive counter is 14)";
CM_ SG_ 587 ONEBOX_4_Resd6 "Profile1A:E2E Reserved";
CM_ SG_ 612 CRC1_264h "Profile1A:E2E CRC (SAE J1850 CRC-8) for 8 Bytes
DataID:0x002B";
CM_ SG_ 612 RollgCntr1_264h "Profile1A:E2E Rolling message counter(the maximum value of Alive counter is 14)";
CM_ SG_ 612 ActrSt_264h "Current state of APB actuator connected to ECU
EPB卡钳执行状态

备注：
①一边夹紧一边释放，按博世最新平台策略，一按照Applied外发。
②0x5:CompletelyReleased（IPB2.0实际按照Reserved）
③0x6:Half Applied（IPB2.0实际按照Reserved）";
CM_ SG_ 612 RWUSt_264h "EPB 后轮防抱死工作状态：
0x1:active仪表持续提示“紧急制动开启”且仪表红“P”灯闪烁，同时点亮制动尾灯，最后1帧信号显示完后结束";
CM_ SG_ 612 IPB_EPBErrorStatus "用于EPB故障显示";
CM_ SG_ 612 EPB_R_1_CRC2_264h "Profile1A:E2E CRC (SAE J1850 CRC-8) for 8 Bytes
DataID:0x002C";
CM_ SG_ 612 EPB_R_1_RollgCntr2_264h "Profile1A:E2E Rolling message counter(the maximum value of Alive counter is 14)";
CM_ SG_ 612 EPB_R_1_Resd2_264h "Profile1A:E2E Reserved";
CM_ SG_ 612 EPB_R_1_CRC3_264h "Profile1A:E2E CRC (SAE J1850 CRC-8) for 8 Bytes
DataID:0x01C5";
CM_ SG_ 612 EPB_R_1_RollgCntr3_264h "Profile1A:E2E Rolling message counter(the maximum value of Alive counter is 14)";
CM_ SG_ 612 EPB_R_1_Resd3_264h "Profile1A:E2E Reserved";
CM_ SG_ 631 CSA_2_AllWarningInfo "EGS全部报警信号
T1C项目，EGS此信号发0x0、0x1、0x4，仪表接收";
CM_ SG_ 788 HighVoltageReq_314h "哨兵模式高压请求";
CM_ SG_ 794 FCM_2_Weather_signal_31Ah "FCM天气信号";
CM_ SG_ 1041 ADS_CRC1_411h "Profile1A:E2E CRC (SAE J1850 CRC-8) for 8 Bytes
DataID:Reserved";
CM_ SG_ 1041 ADS_RollgCntr1_411h "Profile1A:E2E Rolling message counter(the maximum value of Alive counter is 14)";
CM_ SG_ 1041 ADS_Resd1_411h "Profile1A:E2E Reserved";
CM_ SG_ 1041 ADS_RadarWarning0Distance_411h "雷达告警扇区与障碍物距离";
CM_ SG_ 1041 ADS_RadarWarning1Distance_411h "雷达告警扇区与障碍物距离";
CM_ SG_ 1041 ADS_RadarWarning2Distance_411h "雷达告警扇区与障碍物距离";
CM_ SG_ 1041 ADS_RadarWarning3Distance_411h "雷达告警扇区与障碍物距离";
CM_ SG_ 1041 ADS_RadarWarning4Distance_411h "雷达告警扇区与障碍物距离";
CM_ SG_ 1041 ADS_RadarWarning5Distance_411h "雷达告警扇区与障碍物距离";
CM_ SG_ 1041 ADS_CRC2_411h "Profile1A:E2E CRC (SAE J1850 CRC-8) for 8 Bytes
DataID:Reserved";
CM_ SG_ 1041 ADS_RollgCntr2_411h "Profile1A:E2E Rolling message counter(the maximum value of Alive counter is 14)";
CM_ SG_ 1041 ADS_Resd2_411h "Profile1A:E2E Reserved";
CM_ SG_ 1041 ADS_RadarWarning6Distance_411h "雷达告警扇区与障碍物距离";
CM_ SG_ 1041 ADS_RadarWarning7Distance_411h "雷达告警扇区与障碍物距离";
CM_ SG_ 1041 ADS_RadarWarning8Distance_411h "雷达告警扇区与障碍物距离";
CM_ SG_ 1041 ADS_RadarWarning9Distance_411h "雷达告警扇区与障碍物距离";
CM_ SG_ 1041 ADS_RadarWarning10Distance_411h "雷达告警扇区与障碍物距离";
CM_ SG_ 1041 ADS_RadarWarning11Distance_411h "雷达告警扇区与障碍物距离";
CM_ SG_ 1041 ADS_CRC3_411h "Profile1A:E2E CRC (SAE J1850 CRC-8) for 8 Bytes
DataID:Reserved";
CM_ SG_ 1041 ADS_RollgCntr3_411h "Profile1A:E2E Rolling message counter(the maximum value of Alive counter is 14)";
CM_ SG_ 1041 ADS_Resd3_411h "Profile1A:E2E Reserved";
CM_ SG_ 1041 ADS_RadarWarning12Distance_411h "雷达告警扇区与障碍物距离";
CM_ SG_ 1041 ADS_RadarWarning13Distance_411h "雷达告警扇区与障碍物距离";
CM_ SG_ 1041 ADS_RadarWarning14Distance_411h "雷达告警扇区与障碍物距离";
CM_ SG_ 1041 ADS_RadarWarning15Distance_411h "雷达告警扇区与障碍物距离";
CM_ SG_ 1041 ADS_RadarWarning2AcLvl_411h "雷达告警扇区与障碍物声音报警等级";
CM_ SG_ 1041 ADS_RadarWarning1AcLvl_411h "雷达告警扇区与障碍物声音报警等级";
CM_ SG_ 1041 ADS_RadarWarning0AcLvl_411h "雷达告警扇区与障碍物声音报警等级";
CM_ SG_ 1041 ADS_RadarWarning4AcLvl_411h "雷达告警扇区与障碍物声音报警等级";
CM_ SG_ 1041 ADS_RadarWarning3AcLvl_411h "雷达告警扇区与障碍物声音报警等级";
CM_ SG_ 1041 ADS_CRC4_411h "Profile1A:E2E CRC (SAE J1850 CRC-8) for 8 Bytes
DataID:Reserved";
CM_ SG_ 1041 ADS_RollgCntr4_411h "Profile1A:E2E Rolling message counter(the maximum value of Alive counter is 14)";
CM_ SG_ 1041 ADS_Resd4_411h "Profile1A:E2E Reserved";
CM_ SG_ 1041 ADS_RadarWarning7AcLvl_411h "雷达告警扇区与障碍物声音报警等级";
CM_ SG_ 1041 ADS_RadarWarning6AcLvl_411h "雷达告警扇区与障碍物声音报警等级";
CM_ SG_ 1041 ADS_RadarWarning5AcLvl_411h "雷达告警扇区与障碍物声音报警等级";
CM_ SG_ 1041 ADS_RadarWarning10AcLvl_411h "雷达告警扇区与障碍物声音报警等级";
CM_ SG_ 1041 ADS_RadarWarning9AcLvl_411h "雷达告警扇区与障碍物声音报警等级";
CM_ SG_ 1041 ADS_RadarWarning8AcLvl_411h "雷达告警扇区与障碍物声音报警等级";
CM_ SG_ 1041 ADS_RadarWarning12AcLvl_411h "雷达告警扇区与障碍物声音报警等级";
CM_ SG_ 1041 ADS_RadarWarning11AcLvl_411h "雷达告警扇区与障碍物声音报警等级";
CM_ SG_ 1041 ADS_RadarWarning15AcLvl_411h "雷达告警扇区与障碍物声音报警等级";
CM_ SG_ 1041 ADS_RadarWarning14AcLvl_411h "雷达告警扇区与障碍物声音报警等级";
CM_ SG_ 1041 ADS_RadarWarning13AcLvl_411h "雷达告警扇区与障碍物声音报警等级";
CM_ SG_ 1041 ADC_MdcSentryAlarmMod_411h "ADS哨兵模式警告";
CM_ SG_ 1041 ADC_FuncReq_SentryModDetec_411h "哨兵模式功能维持信号";
CM_ SG_ 1041 ADC_FuncReq_SentryModWarn_411h "ADS哨兵模式告警唤醒功能报文";
CM_ SG_ 1041 ADS_CRC5_411h "Profile1A:E2E CRC (SAE J1850 CRC-8) for 8 Bytes
DataID:Reserved";
CM_ SG_ 1041 ADS_RollgCntr5_411h "Profile1A:E2E Rolling message counter(the maximum value of Alive counter is 14)";
CM_ SG_ 1041 ADS_Resd5_411h "Profile1A:E2E Reserved";
CM_ SG_ 1041 ADS_CRC6_411h "Profile1A:E2E CRC (SAE J1850 CRC-8) for 8 Bytes
DataID:Reserved";
CM_ SG_ 1041 ADS_RollgCntr6_411h "Profile1A:E2E Rolling message counter(the maximum value of Alive counter is 14)";
CM_ SG_ 1041 ADS_Resd6_411h "Profile1A:E2E Reserved";
CM_ SG_ 1042 ADS_CRC1_412h "Profile1A:E2E CRC (SAE J1850 CRC-8) for 8 Bytes
DataID:0x01DF";
CM_ SG_ 1042 ADS_RollgCntr1_412h "Profile1A:E2E Rolling message counter(the maximum value of Alive counter is 14)";
CM_ SG_ 1042 ADS_Resd1_412h "Profile1A:E2E Reserved";
CM_ SG_ 1042 ADS_MdcCrtSts_412h "MDC工作状态";
CM_ SG_ 1042 ADS_CRC2_412h "Profile1A:E2E CRC (SAE J1850 CRC-8) for 8 Bytes
DataID:0x01BC";
CM_ SG_ 1042 ADS_RollgCntr2_412h "Profile1A:E2E Rolling message counter(the maximum value of Alive counter is 14)";
CM_ SG_ 1042 ADS_Resd2_412h "Profile1A:E2E Reserved";
CM_ SG_ 1042 ADS_PwrOnOffReq_412h "整车上下电控制请求
泊车上下电和上下Ready";
CM_ SG_ 1042 ADS_ThmPostRun_412h "MDC液冷需求";
CM_ SG_ 1042 ADS_HVCtrlReq_412h "MDC请求高压";
CM_ SG_ 1042 ADS_HiBeamReq_412h "HMA远光灯控制请求";
CM_ SG_ 1042 ADS_HMAStatus_412h "智能远光灯状态";
CM_ SG_ 1042 ADS_hmaOnOffSts_412h "智能大灯辅助(HMA)功能开启/关闭状态信号";
CM_ SG_ 1193 IPB_System_Status "BBF:Base Braking Function
0x0: Boost.Pedal Feel Normal.Full system 
0x1: Boost.Pedal Feel Degrade.ax>6.43
0x2: Boost.Pedal Feel Degrade.ax<6.43
0x3: Boost.Pedal Feel Degrade.ax<6.43 
0x4: No Boost.Pedal Feel Degrade.ax<6.43
Pedal feeling state";
CM_ SG_ 1204 VCU_1_G_CRC "Profile1A:E2E CRC (SAE J1850 CRC-8) for 8 Bytes
DataID:0x005C";
CM_ SG_ 1204 VCU_1_G_RollgCntr "Profile1A:E2E Rolling message counter(the maximum value of Alive counter is 14)";
CM_ SG_ 1204 VCU_1_G_Pwr "instant power（股份信号D01未使用）";
CM_ SG_ 1204 VCU_1_G_AcceleratorPosRaw "真实油门开度
Raw position of the accelerator pedal (unfiltered). Represents always raw pedal position without any other influcence only mandatory to calculated gradient acceleration pedal.";
CM_ SG_ 1204 VCU_1_G_PTReady "PT Ready indication";
CM_ SG_ 1204 VCU_1_G_DriveMode "Driving modes（股份信号D01未使用）";
CM_ SG_ 1204 VCU_1_G_HvBattKeepWarmSts "插枪保温状态";
CM_ SG_ 1204 VCU_1_G_HvBattKeepWarmActiveReq "插枪保温开启请求";
CM_ SG_ 1204 VCU_1_G_HundECAver "average consumption per hundred KM（股份信号D01未使用）";
CM_ SG_ 1204 VCU_1_G_BookChrgSetStsFb "预约充电设置与否状态反馈";
CM_ SG_ 1204 VCU_1_G_EgyRegenLevel "power regeneration level（股份信号D01未使用）";
CM_ SG_ 1204 VCU_1_G_PRNDGearAct "Gear indication";
CM_ SG_ 1209 VCU_2_G_CRC "Profile1A:E2E CRC (SAE J1850 CRC-8) for 8 Bytes
DataID:0x005D";
CM_ SG_ 1209 VCU_2_G_RollgCntr "Profile1A:E2E Rolling message counter(the maximum value of Alive counter is 14)";
CM_ SG_ 1209 VCU_2_G_Resd "Profile1A:E2E Reserved";
CM_ SG_ 1209 VCU_2_G_PowerLimit "power limitation indication";
CM_ SG_ 1209 VCU_2_G_BrakeLightReq "break light during regeneration (calibration)";
CM_ SG_ 1209 VCU_2_G_VehicleSystemFailure "vehicle system failure";
CM_ SG_ 1209 OnekeyHVOffSuccess_4B9h "物理开关一键下高压状态反馈（法规要求）";
CM_ SG_ 1209 VCU_2_G_BootloadSts "0x1:software flash";
CM_ SG_ 1209 VCU_2_G_DischgSts "ICM indication Discharging state";
CM_ SG_ 1209 VCU_2_G_BrakePedalStsValidData "制动踏板状态有效";
CM_ SG_ 1209 VCU_2_G_BrakePedalSts "制动踏板状态";
CM_ SG_ 1209 VCU_2_G_HVReady "HV Ready";
CM_ SG_ 1209 Res_VCU_2_G_Brake_state "break signal

RVM legal request";
CM_ SG_ 1209 VCU_2_G_GasPedalPosition "Driver/Cruise control
This signal including compositive informations which are actual gas pedal position and dummy Cruise control gas pedal position";
CM_ SG_ 1209 VCU_2_G_DrvGearShiftFailureIndcn "0x0:No Indication；（仪表不显示）
0x1:换挡请踩刹车；（驾驶员期望换挡但没有踩下制动踏板时以此提示驾驶员。触发后驾驶员踩下制动踏板或4s后停发）
0x2:换挡车速过高
0x3:换挡请拔下充电枪（P挡且交流枪连接或直流枪连接时拨动换挡杆）
0x4: EPB无法锁止
0x5: EPB无法释放
0x6: 无法切换行驶方向（车辆D/R挡时EGS通讯丢失）
0x7: 换挡杆需求维修（EGS通讯丢失超过3个驾驶循环或发生故障AllWarningInfo!=0x0）";
CM_ SG_ 1209 VCU_2_G_OnekeyHVoffStyle "物理开关一键下高压触发类型";
CM_ SG_ 1212 VCU_3_G_CRC "Profile1A:E2E CRC (SAE J1850 CRC-8) for 8 Bytes
DataID:0x0074";
CM_ SG_ 1212 VCU_3_G_RollgCntr "Profile1A:E2E Rolling message counter(the maximum value of Alive counter is 14)";
CM_ SG_ 1212 VCU_3_G_Resd "Profile1A:E2E Reserved";
CM_ SG_ 1212 VCU_3_G_ActWheelTorqueFA "前轴实际轮端扭矩
Actual wheel torque at FA";
CM_ SG_ 1212 VCU_3_G_ActWheelTorqueRA "后轴实际轮端扭矩
Actual wheel torque at RA";
CM_ SG_ 1229 VCU_4_G_CRC "Profile1A:E2E CRC (SAE J1850 CRC-8) for 8 Bytes
DataID:No ASIL requirements.Not configure
CRC Reserved.";
CM_ SG_ 1229 VCU_4_G_RollgCntr "Profile1A:E2E Rolling message counter(the maximum value of Alive counter is 14)";
CM_ SG_ 1229 VCU_4_G_Resd "Profile1A:E2E Reserved";
CM_ SG_ 1229 VCU_CLTC_RangeAval "Remain CLTC available range";
CM_ SG_ 1229 VCU_DynamicRangeAval "Remain  Dynamic available range";
CM_ SG_ 1229 VCU_HighspdRangeAval "Remain highspeed range";
CM_ SG_ 1229 VCU_WLTC_RangeAval "Remain WLTC available range";
CM_ SG_ 1235 EPS_2_CRC "Profile1A:E2E CRC (SAE J1850 CRC-8) for 8 Bytes
DataID:No ASIL requirements.Not configure
CRC Reserved.";
CM_ SG_ 1235 EPS_2_RollgCntr "Profile1A:E2E Rolling message counter(the maximum value of Alive counter is 14)";
CM_ SG_ 1235 EPS_2_Resd "Profile1A:E2E Reserved";
CM_ SG_ 1235 EPS_Temp_monitor "monitor";
CM_ SG_ 1235 EPS_2_Steer_ReturnRmd "Steer  wheeel return remind(捷途D01）
方向盘未回正文字提示(大屏仪表显示）";
CM_ SG_ 1235 EPS_2_Steer_ReturnRmd_Sts "Steer  wheeel return Sts(捷途D01）
方向盘回正状态";
CM_ SG_ 1235 EPS_AssistanceStyle_Sts "EPS助力工作模式
此信号自驾同样需要";
CM_ SG_ 1235 EPS_2_MFS_ShakeSts "方向盘震动反馈(捷途D01）";
CM_ SG_ 1314 HCU_CRC1_522h "Profile1A:E2E CRC (SAE J1850 CRC-8) for 8 Bytes
DataID:Reserved";
CM_ SG_ 1314 HCU_RollgCntr1_522h "Profile1A:E2E Rolling message counter(the maximum value of Alive counter is 14)";
CM_ SG_ 1314 HCU_V2lDisChgBck "V2L外放电开关反馈";
CM_ SG_ 1314 HCU_DisChgMemFed "V2L外放电记忆开关反馈";
CM_ SG_ 1314 HCU_V2VDisChgBck "V2V放电开关反馈";
CM_ SG_ 1314 HCU_V2l_IntlDisChgBck "V2L内放电开关反馈";
CM_ SG_ 1314 HCU_FuelDetnOpDefeated "燃油检测开启失败提示";
CM_ SG_ 1314 HCU_FuelDetnModSwtFed "燃油检测开关反馈";
CM_ SG_ 1314 HCU_FuelDetnStateFed "燃油检测模式状态反馈";
CM_ SG_ 1314 HCU_HVDownRepairModeFed "断高压维修模式开关反馈";
CM_ SG_ 1314 HCU_SumFuCns "自清零后累计百公里油耗显示(仅仪表使用)";
CM_ SG_ 1314 HCU_TrailerMode "被拖模式开关反馈";
CM_ SG_ 1314 HCU_TABSwtFed_522h "ICC坦克转向开关反馈
0x0:Not_Active 使能位
0x1:Active 激活
0x2:Stand_by 就绪
0x3:Failed 失败";
CM_ SG_ 1314 HCU_MotSelfHeatLvlReq "电驱自发热档位需求";
CM_ SG_ 1314 HCU_MotSelfHeatEnReq "电驱自发热使能开关";
CM_ SG_ 1314 HCU_KeyDriveModememory "驾驶模式记忆开关反馈";
CM_ SG_ 1314 HCU_DrivePowerDispSetFed "驱动系统功率显示方式开关反馈";
CM_ SG_ 1314 HCU_TCMStsReq_522h "TCM使能状态";
CM_ SG_ 1314 HCU_EXPERTNormFed "专家模式动力设置标准模式开关反馈";
CM_ SG_ 1314 HCU_4LModeFed "低速四驱开关反馈";
CM_ SG_ 1314 HCU_EXPERTEcoFed "专家模式动力设置柔和模式开关反馈";
CM_ SG_ 1314 HCU_SingleRegnRmn "当车机收到HCU发送信号“HCU_SingleRegnRmn =0x1”时，弹框提示“单踏板受限已退出，请注意安全驾驶！”，并播放报警音持续3s；
当车机收到HCU发送信号“HCU_SingleRegnRmn=0x0”时，停止提示，并停止报警音；";
CM_ SG_ 1314 HCU_DRIFTModeSts "通过大屏设置漂移模式灵敏度开关反馈
0x0:不动作
0x1:入门
0x2:大师
0x3:专家";
CM_ SG_ 1314 HCU_CRC2_522h "Profile1A:E2E CRC (SAE J1850 CRC-8) for 8 Bytes
DataID:Reserved";
CM_ SG_ 1314 HCU_RollgCntr2_522h "Profile1A:E2E Rolling message counter(the maximum value of Alive counter is 14)";
CM_ SG_ 1314 HCU_EXPERTAWDFed "专家模式驱动形式四驱开关设置反馈";
CM_ SG_ 1314 HCU_EXPERTRWDFed "专家模式驱动形式后驱开关设置反馈";
CM_ SG_ 1314 HCU_CrossaxisFed "专家模式交叉轴模式开关设置反馈";
CM_ SG_ 1314 HCU_EXPERTSportFed "专家模式动力设置激进模式开关反馈";
CM_ SG_ 1314 HCU_StopChrgnModeFed "驻车发电模式开关反馈";
CM_ SG_ 1314 HCU_StopChrgnFed "驻车发电开关反馈";
CM_ SG_ 1314 HCU_CLIMBFed "防溜设置开关反馈";
CM_ SG_ 1314 HCU_EXPERTAutoFed "专家模式驱动形式Auto开关设置反馈";
CM_ SG_ 1314 HCU_HEV_FunctionLimit "仪表文字提示“HEV模式不可用”";
CM_ SG_ 1314 HCU_ParkingChargeReminder "仪表文字提示“请先驻车再充电”";
CM_ SG_ 1314 HCU_PowerCut "仪表文字提示“动力即将切断，请靠边停车”";
CM_ SG_ 1314 HCU_IMMOReleaseSignal "防盗报警指示灯信号";
CM_ SG_ 1314 HCU_LVPowSupSYSAbn_lit "低压供电系统异常状态";
CM_ SG_ 1314 HCU_ChrgnFctMemSt "强制保电记忆开关反馈";
CM_ SG_ 1314 HCU_PowerModeChangeInhibit "仪表文字提示“为保障越野性能，模式无法切换”";
CM_ SG_ 1314 HCU_DisconnectChagWarn "仪表文字提示“请拔下充电枪”";
CM_ SG_ 1314 HCU_EngineRunClmReq "仪表文字提示“空调请求发动机运行中”";
CM_ SG_ 1314 HCU_VehicleSpeedMax_Limit "仪表文字提示“最高车速受限，请尽快联系售后检修”";
CM_ SG_ 1314 HCU_AccleAbility_Limit "仪表文字提示“加速性能受限，请尽快联系售后检修”";
CM_ SG_ 1314 HCU_DriveInhibit_GearP "仪表文字提示“动力受限，进入P挡后无法再次行驶，请尽快联系售后检修”";
CM_ SG_ 1314 HCU_SetModeNotChange "仪表文字提示“模式禁止切换”";
CM_ SG_ 1314 HCU_UTURNSnowFed "极限调头雪地场景反馈";
CM_ SG_ 1314 HCU_PowerLevel "仪表驱动能力等级";
CM_ SG_ 1314 HCU_TowingModeEna "大屏被拖提醒文字提示ICC接收
0x1时，大屏文字提示“切换至被拖模式需满足以下条件：1、挡位处于P挡；2、踩下刹车；3、车辆不在充电状态”";
CM_ SG_ 1314 HCU_LeaveVehicleWarning "仪表声音提醒";
CM_ SG_ 1314 HCU_DedicatedModeInhibit "仪表文字提示“当前模式不可用，请切换至越野模式”";
CM_ SG_ 1314 HCU_DisChargeStopFault "0x1时仪表文字提示“电池电量过低，放电停止”0x2时仪表文字提示“燃油不足，放电停止”";
CM_ SG_ 1314 HCU_RearEDLSts "后差速锁状态
0x0:不锁
0x1:解锁
0x2:锁止
0x3:切换提醒
0x4:不满足锁止条件
0x5:差速锁无法锁止故障
0x6:差速锁无法解锁故障";
CM_ SG_ 1314 HCU_FrntEDLSts "前差速锁状态
0x0: 不锁
0x1: 解锁
0x2：锁止
0x3：切换提醒
0x4：不满足锁止条件
0x5：差速锁无法锁止故障
0x6：差速锁无法解锁故障
0x7：提示需挂入后锁和4L
0x8：提示开启后锁
0x9：提示开启4L";
CM_ SG_ 1314 HCU_CRC3_522h "Profile1A:E2E CRC (SAE J1850 CRC-8) for 8 Bytes
DataID:Reserved";
CM_ SG_ 1314 HCU_RollgCntr3_522h "Profile1A:E2E Rolling message counter(the maximum value of Alive counter is 14)";
CM_ SG_ 1314 HCU_CruiseLimitSpeedValue "定速巡航设定车速";
CM_ SG_ 1314 HCU_DriveMode_JT "驾驶模式反馈
0x0:经济
0x1:标准
0x2:运动
0x3:雪/草地
0x4:泥地
0x5:越野
0x6:沙地
0x7:岩石
0x8:专家
0x9:智能
0xA:涉水
0xB:极限掉头
0xC:漂移
0xD:拖挂
0xE:越野竞速
0xF:晕车舒缓
0x10:智慧能量管理
0x11:纵横征服
0x12~0x1F：预留";
CM_ SG_ 1314 HCU_SocManageFed "Soc_Manage_Feedback";
CM_ SG_ 1314 HCU_SinglePedalMemFed "单踏板记忆开关反馈";
CM_ SG_ 1314 HCU_CCOSwtFed "越野蠕行开关反馈";
CM_ SG_ 1314 HCU_Pwr "instant_power";
CM_ SG_ 1314 HCU_UTURNSandFed "极限调头泥地场景开关反馈";
CM_ SG_ 1314 HCU_CruiseControlStatus "定速巡航指示灯";
CM_ SG_ 1314 HCU_EXPERTEESPSet "关闭牵引力控制系统&车身稳定控制系统（TCS&VDC_OFF）
全开（TCS、VDC等与ESP有关功能全部开启）
全关（TCS、VDC及RMI放侧翻、DTC发动机拖滞力矩管理）";
CM_ SG_ 1314 HCU_EgyRegenLevel "power_regeneration_level";
CM_ SG_ 1314 HCU_CRC4_522h "Profile1A:E2E CRC (SAE J1850 CRC-8) for 8 Bytes
DataID:0x0114";
CM_ SG_ 1314 HCU_RollgCntr4_522h "Profile1A:E2E Rolling message counter(the maximum value of Alive counter is 14)";
CM_ SG_ 1314 HCU_EngyFlowToDisp "0x0:初始化
0x1:无能量流状态
0x2:发动机单独运行
0x3:纯电前驱
0x4:纯电前驱回馈
0x5:纯电后驱
0x6:纯电后驱回馈
0x7:纯电四驱
0x8:纯电四驱回馈
0x9:串联前驱电池充电
0xA:串联前驱电池放电
0xB:串联前驱电池无电流
0xC:串联前驱回馈
0xD:串联后驱电池充电
0xE:串联后驱电池放电
0xF:串联后驱电池无电流
0x10:串联后驱回馈
0x11:串联四驱电池充电
0x12:串联四驱电池放电
0x13:串联四驱电池无电流
0x14:串联四驱回馈
0x15:并联前驱电池充电
0x16:并联前驱电池放电
0x17:并联前驱电池无电流
0x18:并联前驱回馈
0x19:并联四驱电池充电
0x1A:并联四驱电池放电
0x1B:并联四驱电池无电流
0x1C:并联四驱回馈
0x1D:原地发电电池充电
0x1E:原地发电电池放电
0x1F:原地发电电池无电流";
CM_ SG_ 1314 HCU_UTURNGrassFed "极限调头草地场景反馈";
CM_ SG_ 1314 HCU_UTURNMudFed "极限调头沙地场景开关反馈";
CM_ SG_ 1314 HCU_LTCDispFed "续航里程选择开关反馈";
CM_ SG_ 1314 HCU_iTAS_Warn "0x0: 无提示
0x1:iTAS功能已激活，无法锁止后桥差速锁
0x2:请释放EPB
0x3:当前车速过高，请减速
0x4：制动盘温度过高，极限掉头功能已退出
0x5：车辆被卡住，极限掉头功能退出
0x6：极限掉头使用时间到达极限，功能退出
0x7：请切换至D档开启极限掉头";
CM_ SG_ 1314 HCU_iCCO_Warn "0x0: 无提示
0x1:请释放EPB
0x2:当前车速过高，请减速
0x3:请关好车门，系好安全带
0x4:请切换至D档或N档开启越野蠕行
0x5:请关闭 APA/ACC/CC巡航
0x6:请退出HDC陡坡缓降/自动驻车
0x7:请手动切换驾驶模式至雪地或泥地或沙地或岩石
0x8:请踩制动踏板
0x9:iCCO越野蠕行已退出";
CM_ SG_ 1314 HCU_DriveModeChangeFail "驾驶模式切换不满足条件，提示“请停车后退出当前驾驶模式”";
CM_ SG_ 1314 HCU_25_Crossaxis_Warn "0x0: 无提示
0x1:请释放EPB
0x2:当前车速过高，交叉轴功能已退出
0x3:请切换至D档开启交叉轴功能
0x4:请关好车门，系好安全带
0x5:请将车辆静止后踩制动踏板
0x6:进入交叉轴模式后进行空簧高度调节";
CM_ SG_ 1314 HCU_25_EDLFed "中央差速锁显示信号";
CM_ SG_ 1314 HCU_DraggingModeRemind "0x0: 无提示
0x1:禁用ECO和越野模式
0x2:拖挂模式下仅支持Normal和Sport
0x3:ECO和越野模式恢复
0x4~0x7:预留";
CM_ SG_ 1314 HCU_iTASSceneReq "iTAS场景选择信息";
CM_ SG_ 1314 HCU_25_iTAS_SlopWarn "极限调头坡度条件不满足提醒
0x0:无提示
0x1:地面坡度过大
0x2~0x3:Reserved";
CM_ SG_ 1314 HCU_ExterTempLowHint "0x0:无提示
0x1:环境温度低切换为HEV模式
0x2:环境温度过低发动机运行中";
CM_ SG_ 1314 HCU_iTAS_Active "极限掉头激活状态（仪表）";
CM_ SG_ 1314 HCU_25_VehSpdOffroadRmn "漂移，掉头，专家，交叉轴，越野蠕行，越野竞速功能，用户在车辆未静止状态下点退出按钮或硬开关，仪表接收该信号0x1后显示“请将车辆禁止后再设置”";
CM_ SG_ 1314 HCU_DrivingModReq "HCU给IPB映射驾驶模式";
CM_ SG_ 1314 HCU_25_ADS_FctSts "智能驾驶功能激活状态";
CM_ SG_ 1314 HCU_25_DRIFTModeSetReq "漂移灵敏度开启信号(HCU判断完成后外发)";
CM_ SG_ 1314 HCU_25_CrossaxisReq "交叉轴开启信号(HCU判断完成后外发)";
CM_ SG_ 1314 HCU_25_CCOSwtReq "CCO开启信号(HCU判断完成后外发)";
CM_ SG_ 1314 HCU_CRC5_522h "Profile1A:E2E CRC (SAE J1850 CRC-8) for 8 Bytes
DataID:Reserved";
CM_ SG_ 1314 HCU_RollgCntr5_522h "Profile1A:E2E Rolling message counter(the maximum value of Alive counter is 14)";
CM_ SG_ 1314 HCU_25_ErrorCode "HCU接收各控制器故障等级后处理的故障码";
CM_ SG_ 1314 HCU_25_ErrorCount "用于上报当前HCU故障总数";
CM_ SG_ 1314 HCU_25_iDRIFT_Warn "0x0:无提示
0x1:请关好车门，系好安全带
0x2:请将车辆停止
0x3:系统故障，漂移模式暂无法开启
0x4:进入漂移模式后进行空簧高度调节";
CM_ SG_ 1314 HCU_25_SetVehSpdOffroad "越野模式切换车速条件不满足提示
0x0:无提示
0x1:请将车辆静止后再设置
0x2~0x3:Reserved";
CM_ SG_ 1314 HCU_25_LaunchMod_Warn "越野竞速弹射模式弹窗提示
0x0:无提示
0x1:弹射模式已激活，松开制动踏板，开始弹射
0x2:弹射模式已退出
0x3:条件不满足，弹射模式不可用
0x4~0x7:Reserved";
CM_ SG_ 1314 HCU_25_TAB_Warn "TAB功能提醒(T1J FL2华为智驾使用，D01及D01华为智驾版不使用)";
CM_ SG_ 1314 HCU_25_CCO_TextDisp "CCO功能提示信息
越野蠕行功能提示
(T1J FL2华为智驾使用，D01及D01华为智驾版不使用)";
CM_ SG_ 1314 HCU_25_DCM_Warn "纵横征服功能提示
0x0:No_Warn
0x1:请释放 EPB
0x2:请关好车门,系好安全带
0x3:请切换至D/R档开启攀爬模式
0x4:请关闭APA/ACC/CC巡航
0x5:请退出HDC 陡坡缓降/AVH自动驻车
0x6:请踩制动踏板
0x7:纵横征服 已退出
0x8: 请在车辆静止时进入或退出该模式
0x9:功率限制，功能无法正常使用
0xA: 请丢开加速踏板
0xB:请踩制动
0xC~0xF:Reserved";
CM_ SG_ 1314 HCU_25_CCMFed "攀爬设置开关反馈";
CM_ SG_ 1314 HCU_25_TABReq "HCU发送TAB功能请求(T1J FL2华为智驾使用，D01及D01华为智驾版不使用)";
CM_ SG_ 1314 HCU_SumElecCns "自清零后累计百公里电耗显示(仅仪表使用)";
CM_ SG_ 1314 HCU_CrossBorderSts "HCU 反馈飞车模式执行情况
0x1: On 表示飞车模式限制已开启
0x2: Off 表示飞车模式限制未开启";
CM_ SG_ 1314 HCU_DischgSetSOCFed "放电SOC设置状态反馈
0xFE:Abnormal
0xFF:Invalid";
CM_ SG_ 1314 HCU_facCleverDrvAct_522h "驾驶运动因子";
CM_ SG_ 1314 HCU_stCleverDrvAct_522h "智慧驾驶风格状态";
CM_ SG_ 1314 HCU_stCleverRgnAct_522h "智慧能量回收状态";
CM_ SG_ 1314 HCU_stCleverMainAct_522h "智慧能量管理状态";
CM_ SG_ 1314 EnergySavingModeSts_522h "节能模式设置反馈";
CM_ SG_ 1314 HCU_facCleverDrvActRstFed_522h "驾驶运动因子重置反馈";
CM_ SG_ 1314 HCU_SailramainingT_Indc_522h "剩余航行时间（对比）,真实显示的";
CM_ SG_ 1314 HCU_ATCM_Operation_REQ_522h "航行模式按键确认信号
0x0:Not Active
0x1:进入航行提示  Switch to sailfunc indiction
0x2:进入上滩提示Switch to upbeach indiction
0x3:陆地时点击航行物理开关误操作提示 misoperation indiction: press sailfunc sw when conenmod 
0x4:陆地时点击上滩物理开关误操作提示misoperation indiction: press upbeach  sw when conenmod 
0x5:涉水时点击上滩物理开关误操作提示misoperation indiction: press upbeach sw when wadests
0x6:reserved
0x7:reserved";
CM_ SG_ 1314 HCU_ModeSwFailureIndc_522h "模式切换失效提示
0x0: Not Active
0x1:进入航行失败：车门未关
Entry navigation failed: Car door is not closed
0x2：进入航行失败：后视镜未展开
Entry navigation failed: Rearview mirror not deployed
0x3:进入航行失败：进排气防水阀故障
Entry navigation failed: Intake and exhaust waterproof valve malfunction
0x4：进入航行失败：车速过大
Entry navigation failed: Speed too fast
0x5：进入航行失败：电量过低
Entry navigation failed: Low battery
0x6：进入航行失败：空调放水阀故障|散热风扇故障
Entry navigation failed: Air conditioning drain valve malfunction| Cooling fan malfunction";
CM_ SG_ 1314 HCU_Sailmode_522h "涉水模式
0x0:Convenmod
0x1:SalWadeSts  浅涉水
0x2:DpWadeSts 深涉水（保留）
0x3:SailingFunc  航行
0x4:UpbeachSts  上滩
0x5:WaitfinspSts 待检（保留）
0x6:EmerfloatingSts 应急浮水
0x7:Reserved2";
CM_ SG_ 1314 HCU_CarSickRelfModeFb "晕车舒缓状态反馈";
CM_ SG_ 1314 HCU_DeepSnowSts_522h "深雪模式状态信号";
CM_ SG_ 1314 DriveModeChangeFailReason_522h "驾驶模式切换失败原因提示";
CM_ SG_ 1314 HCU_CLIMBDisReason_522h "攀爬防溜设置失败原因提示
0x0:不提醒
0x1:请踩刹车上Ready
0x2:请挂入D档或N档
0x3:请切换到岩石模式
0x4:底盘限扭系统激活
0x5:请关闭智驾功能后重试
0x6:请减速后重试
0x7:驱动系统故障
0x8:纵向加速度无效
0x9:请退出越野蠕行
0xA:制动辅助不可用
0xB:IPB系统故障";
CM_ SG_ 1314 HCU_CarSickRelfModeDisReason "晕车舒缓开启失败原因
0x0:不提示
0x1:请退出越野模式
0x2:请退出越野蠕行
0X3:请退出节能模式
0X4:请退出拖挂模式
0X5:请退出被拖模式
0X6:请退出定速巡航模式
0X7:请退出智驾模式";
CM_ SG_ 1314 HCU_DCMSwtFed "纵横征服模式场景
0x0:not active
0x1:泥沙脱困
0x2:雪地暴行
0x3:攀爬挑战
0x4:丛林探路
0x5:拔河
0x6:救援
0x7:Reserved";
CM_ SG_ 1314 HCU_LightSandSts_522h "浅沙模式：
0x0:信号无作用
0x1:浅沙模式激活
0x1:浅沙模式关闭";
CM_ SG_ 1582 RMR_RMCU "If set to 1 to force the network management of all other nodes on the bus into the re-peat message state.";
CM_ SG_ 1582 RMCU_Wakeup_Poweron "KL15 ON";
CM_ SG_ 1582 RMCU_Wakeup_NM "NM报文";
CM_ SG_ 1582 RMCU_Wakeup_Diag "Wakeup Source3 Reserved";
CM_ SG_ 1582 RMCU_Awake_Poweron "KL15 ON";
CM_ SG_ 1582 RMCU_Awake_NM "Awake Reason2 Reserved";
CM_ SG_ 1582 RMCU_Awake_Diag "接收到本部件相关的诊断报文";
CM_ SG_ 1582 RMCU_Awake_Discharge "放电中且放电未超时";
CM_ SG_ 1582 RMCU_Awake_HVON "整车处于高压状态";
BA_DEF_ SG_ "ASIL" ENUM "QM","A","B","C","D";
BA_DEF_ SG_ "E2EDataLength" INT 0 65535;
BA_DEF_ SG_ "GenSigInactiveValue" HEX 0 80000000;
BA_DEF_ SG_ "GenSigInvalidValue" HEX 0 281474976710655;
BA_DEF_ SG_ "GenSigStartValue" HEX 0 80000000;
BA_DEF_ SG_ "GenSigSendType" ENUM "Cyclic","OnWrite","OnWriteWithRepetition","OnChange","OnChangeWithRepetition","IfActive","IfActiveWithRepetition","NoSigSendType";
BA_DEF_ BO_ "CANFD_BRS" ENUM "0","1";
BA_DEF_ BO_ "DiagUudtResponse" ENUM "True","False";
BA_DEF_ BO_ "GenMsgCycleTime" INT 0 65535;
BA_DEF_ BO_ "GenMsgCycleTimeFast" INT 0 65535;
BA_DEF_ BO_ "GenMsgDelayTime" INT 0 65535;
BA_DEF_ BO_ "GenMsgILSupport" ENUM "No","Yes";
BA_DEF_ BO_ "GenMsgNrOfRepetition" INT 0 255;
BA_DEF_ BO_ "GenMsgSendType" ENUM "Cyclic","Event","IfActive","CE","CA","NoMsgSendType";
BA_DEF_ BO_ "MsgType" ENUM "IL","NM","DIAG","APPL";
BA_DEF_ BO_ "Msg_ASIL" ENUM "vector_leerstring","QM","A","B","C","D";
BA_DEF_ BO_ "NmAsrMessage" ENUM "No","Yes";
BA_DEF_ BO_ "NmMessage" ENUM "No","Yes";
BA_DEF_ BO_ "SCP_AuthInfoTxLength" INT 9 512;
BA_DEF_ BO_ "SCP_FreshnessValueLength" INT 0 512;
BA_DEF_ BO_ "SCP_FreshnessValueTxLength" INT 0 512;
BA_DEF_ BO_ "VFrameFormat" ENUM "StandardCAN","ExtendedCAN","reserved","J1939PG","reserved","reserved","reserved","reserved","reserved","reserved","reserved","reserved","reserved","reserved","StandardCAN_FD","ExtendedCAN_FD";
BA_DEF_DEF_ "ASIL" "QM";
BA_DEF_DEF_ "E2EDataLength" 64;
BA_DEF_DEF_ "GenSigInactiveValue" 0;
BA_DEF_DEF_ "GenSigInvalidValue" 0;
BA_DEF_DEF_ "GenSigStartValue" 0;
BA_DEF_DEF_ "GenSigSendType" "NoSigSendType";
BA_DEF_DEF_ "CANFD_BRS" "1";
BA_DEF_DEF_ "DiagUudtResponse" "True";
BA_DEF_DEF_ "GenMsgCycleTime" 0;
BA_DEF_DEF_ "GenMsgCycleTimeFast" 0;
BA_DEF_DEF_ "GenMsgDelayTime" 0;
BA_DEF_DEF_ "GenMsgILSupport" "Yes";
BA_DEF_DEF_ "GenMsgNrOfRepetition" 0;
BA_DEF_DEF_ "GenMsgSendType" "Cyclic";
BA_DEF_DEF_ "MsgType" "IL";
BA_DEF_DEF_ "Msg_ASIL" "vector_leerstring";
BA_DEF_DEF_ "NmAsrMessage" "No";
BA_DEF_DEF_ "NmMessage" "No";
BA_DEF_DEF_ "SCP_AuthInfoTxLength" 28;
BA_DEF_DEF_ "SCP_FreshnessValueLength" 48;
BA_DEF_DEF_ "SCP_FreshnessValueTxLength" 4;
BA_DEF_DEF_ "VFrameFormat" "J1939PG";
BA_ "GenMsgCycleTime" BO_ 555 20;
BA_ "VFrameFormat" BO_ 555 14;
BA_ "GenMsgCycleTime" BO_ 571 20;
BA_ "VFrameFormat" BO_ 571 14;
BA_ "GenMsgCycleTime" BO_ 572 20;
BA_ "VFrameFormat" BO_ 572 14;
BA_ "GenMsgCycleTime" BO_ 587 20;
BA_ "VFrameFormat" BO_ 587 14;
BA_ "GenMsgCycleTime" BO_ 612 20;
BA_ "VFrameFormat" BO_ 612 14;
BA_ "GenMsgCycleTime" BO_ 631 20;
BA_ "VFrameFormat" BO_ 631 14;
BA_ "GenMsgCycleTime" BO_ 788 50;
BA_ "VFrameFormat" BO_ 788 14;
BA_ "GenMsgCycleTime" BO_ 794 50;
BA_ "VFrameFormat" BO_ 794 14;
BA_ "GenMsgCycleTime" BO_ 1041 100;
BA_ "VFrameFormat" BO_ 1041 14;
BA_ "GenMsgCycleTime" BO_ 1042 100;
BA_ "VFrameFormat" BO_ 1042 14;
BA_ "GenMsgCycleTime" BO_ 1193 100;
BA_ "VFrameFormat" BO_ 1193 14;
BA_ "GenMsgCycleTime" BO_ 1204 100;
BA_ "VFrameFormat" BO_ 1204 14;
BA_ "GenMsgCycleTime" BO_ 1209 100;
BA_ "VFrameFormat" BO_ 1209 14;
BA_ "GenMsgCycleTime" BO_ 1212 100;
BA_ "VFrameFormat" BO_ 1212 14;
BA_ "GenMsgCycleTime" BO_ 1229 100;
BA_ "VFrameFormat" BO_ 1229 14;
BA_ "GenMsgCycleTime" BO_ 1235 100;
BA_ "VFrameFormat" BO_ 1235 14;
BA_ "GenMsgCycleTime" BO_ 1314 100;
BA_ "VFrameFormat" BO_ 1314 14;
BA_ "GenMsgCycleTime" BO_ 1582 1000;
BA_ "NmMessage" BO_ 1582 1;
BA_ "DiagUudtResponse" BO_ 1582 1;
BA_ "MsgType" BO_ 1582 1;
BA_ "NmAsrMessage" BO_ 1582 1;
BA_ "GenMsgILSupport" BO_ 1582 0;
BA_ "VFrameFormat" BO_ 1582 0;
BA_ "GenSigSendType" SG_ 555 ONEBOX_3_CRC1 0;
BA_ "GenSigSendType" SG_ 555 ONEBOX_3_RollgCntr1 0;
BA_ "GenSigSendType" SG_ 555 ONEBOX_3_Resd1 0;
BA_ "GenSigSendType" SG_ 555 ONEBOX_3_AVHSts 0;
BA_ "GenSigInvalidValue" SG_ 555 VehicleStandstill 2;
BA_ "ASIL" SG_ 555 VehicleStandstill 2;
BA_ "GenSigSendType" SG_ 555 VehicleStandstill 0;
BA_ "GenSigStartValue" SG_ 555 NoBrakeForce 1;
BA_ "ASIL" SG_ 555 NoBrakeForce 2;
BA_ "GenSigSendType" SG_ 555 NoBrakeForce 0;
BA_ "GenSigSendType" SG_ 555 ONEBOX_3_AVHFailSts 0;
BA_ "GenSigSendType" SG_ 555 Reserved_EDCActive 0;
BA_ "ASIL" SG_ 555 ECDTempOff 2;
BA_ "GenSigSendType" SG_ 555 ECDTempOff 0;
BA_ "GenSigSendType" SG_ 555 DCFail 0;
BA_ "ASIL" SG_ 555 CDDActive 2;
BA_ "GenSigSendType" SG_ 555 CDDActive 0;
BA_ "ASIL" SG_ 555 CDDAvailable 2;
BA_ "GenSigSendType" SG_ 555 CDDAvailable 0;
BA_ "GenSigSendType" SG_ 555 Reserved_ESPLampInformation 0;
BA_ "GenSigInvalidValue" SG_ 555 TorqueMaxLimt 255;
BA_ "GenSigStartValue" SG_ 555 TorqueMaxLimt 255;
BA_ "GenSigSendType" SG_ 555 TorqueMaxLimt 0;
BA_ "GenSigSendType" SG_ 555 ClutchOpenRequest 0;
BA_ "GenSigSendType" SG_ 555 QDCACC 0;
BA_ "GenSigSendType" SG_ 555 ONEBOX_3_CRC2 0;
BA_ "GenSigSendType" SG_ 555 ONEBOX_3_RollgCntr2 0;
BA_ "GenSigSendType" SG_ 555 ONEBOX_3_Resd2 0;
BA_ "GenSigInvalidValue" SG_ 555 ONEBOX_3_WheelBrakeForce 65535;
BA_ "GenSigStartValue" SG_ 555 ONEBOX_3_WheelBrakeForce 31250;
BA_ "ASIL" SG_ 555 ONEBOX_3_WheelBrakeForce 2;
BA_ "GenSigSendType" SG_ 555 ONEBOX_3_WheelBrakeForce 0;
BA_ "GenSigStartValue" SG_ 555 TorqueIncreaseReqRA 32768;
BA_ "ASIL" SG_ 555 TorqueIncreaseReqRA 3;
BA_ "GenSigSendType" SG_ 555 TorqueIncreaseReqRA 0;
BA_ "GenSigStartValue" SG_ 555 TorqueReductReqRA 32768;
BA_ "ASIL" SG_ 555 TorqueReductReqRA 3;
BA_ "GenSigSendType" SG_ 555 TorqueReductReqRA 0;
BA_ "GenSigSendType" SG_ 555 ONEBOX_3_CRC3 0;
BA_ "GenSigSendType" SG_ 555 ONEBOX_3_RollgCntr3 0;
BA_ "GenSigSendType" SG_ 555 ONEBOX_3_Resd3 0;
BA_ "GenSigStartValue" SG_ 555 TorqueIncreaseReqFA 32768;
BA_ "ASIL" SG_ 555 TorqueIncreaseReqFA 3;
BA_ "GenSigSendType" SG_ 555 TorqueIncreaseReqFA 0;
BA_ "GenSigStartValue" SG_ 555 TorqueReductReqFAFsat 32768;
BA_ "ASIL" SG_ 555 TorqueReductReqFAFsat 3;
BA_ "GenSigSendType" SG_ 555 TorqueReductReqFAFsat 0;
BA_ "GenSigSendType" SG_ 555 ONEBOX_3_CRC4 0;
BA_ "GenSigSendType" SG_ 555 ONEBOX_3_RollgCntr4 0;
BA_ "GenSigSendType" SG_ 555 ONEBOX_3_Resd4 0;
BA_ "GenSigStartValue" SG_ 555 TorqueIncreaseReqRAValidData 1;
BA_ "ASIL" SG_ 555 TorqueIncreaseReqRAValidData 3;
BA_ "GenSigSendType" SG_ 555 TorqueIncreaseReqRAValidData 0;
BA_ "GenSigStartValue" SG_ 555 TorqueReductReqRAValidData 1;
BA_ "ASIL" SG_ 555 TorqueReductReqRAValidData 3;
BA_ "GenSigSendType" SG_ 555 TorqueReductReqRAValidData 0;
BA_ "GenSigStartValue" SG_ 555 TorqueIncreaseReqFAValidData 1;
BA_ "ASIL" SG_ 555 TorqueIncreaseReqFAValidData 3;
BA_ "GenSigSendType" SG_ 555 TorqueIncreaseReqFAValidData 0;
BA_ "GenSigStartValue" SG_ 555 TorqueReductReqFAFastValidData 1;
BA_ "ASIL" SG_ 555 TorqueReductReqFAFastValidData 3;
BA_ "GenSigSendType" SG_ 555 TorqueReductReqFAFastValidData 0;
BA_ "GenSigSendType" SG_ 555 ESP_Park_CurrentSystemStatus 0;
BA_ "GenSigSendType" SG_ 555 ESP_Pilot_CurrentSystemStatus 0;
BA_ "ASIL" SG_ 555 PlungerPressureValidData_22Bh 3;
BA_ "GenSigSendType" SG_ 555 PlungerPressureValidData_22Bh 0;
BA_ "ASIL" SG_ 555 IPB_InputRodStrokeStatus_22Bh 2;
BA_ "GenSigSendType" SG_ 555 IPB_InputRodStrokeStatus_22Bh 0;
BA_ "GenSigSendType" SG_ 555 SCMActive 0;
BA_ "GenSigSendType" SG_ 555 SCMAvalable 0;
BA_ "GenSigInvalidValue" SG_ 555 IPB_PlungerPressure_22Bh 1023;
BA_ "ASIL" SG_ 555 IPB_PlungerPressure_22Bh 3;
BA_ "GenSigSendType" SG_ 555 IPB_PlungerPressure_22Bh 0;
BA_ "GenSigStartValue" SG_ 555 IPB_InputRodStroke_22Bh 100;
BA_ "ASIL" SG_ 555 IPB_InputRodStroke_22Bh 2;
BA_ "GenSigSendType" SG_ 555 IPB_InputRodStroke_22Bh 0;
BA_ "ASIL" SG_ 555 BrakePedalPressStsValidData 4;
BA_ "GenSigSendType" SG_ 555 BrakePedalPressStsValidData 0;
BA_ "ASIL" SG_ 555 DTCActive 2;
BA_ "GenSigSendType" SG_ 555 DTCActive 0;
BA_ "GenSigSendType" SG_ 555 DTCAvailable 0;
BA_ "GenSigSendType" SG_ 555 DTC_Intervention 0;
BA_ "ASIL" SG_ 555 BrakePedalPressSts 4;
BA_ "GenSigSendType" SG_ 555 BrakePedalPressSts 0;
BA_ "GenSigSendType" SG_ 555 ONEBOX_3_CRC5 0;
BA_ "GenSigSendType" SG_ 555 ONEBOX_3_RollgCntr5 0;
BA_ "GenSigSendType" SG_ 555 ONEBOX_3_Resd5 0;
BA_ "GenSigSendType" SG_ 555 ONEBOX_CRC6_22Bh 0;
BA_ "GenSigSendType" SG_ 555 ONEBOX_RollgCntr6_22Bh 0;
BA_ "GenSigSendType" SG_ 555 ONEBOX_Resd6_22Bh 0;
BA_ "ASIL" SG_ 571 DrvDoorSts_23Bh 1;
BA_ "GenSigSendType" SG_ 571 DrvDoorSts_23Bh 0;
BA_ "ASIL" SG_ 571 DrvSeatBeltSW_23Bh 1;
BA_ "GenSigSendType" SG_ 571 DrvSeatBeltSW_23Bh 0;
BA_ "GenSigSendType" SG_ 572 ONEBOX_7_CRC1 0;
BA_ "GenSigSendType" SG_ 572 ONEBOX_7_RollgCntr1 0;
BA_ "GenSigSendType" SG_ 572 ONEBOX_7_Resd1 0;
BA_ "GenSigSendType" SG_ 572 ONEBOX_7_Crossaxis_TqtTrq 0;
BA_ "GenSigSendType" SG_ 572 ONEBOX_7_iCCO_TqtTrq 0;
BA_ "GenSigSendType" SG_ 572 ONEBOX_7_TAB_Active 0;
BA_ "GenSigSendType" SG_ 572 ONEBOX_7_iTASDangerQuit 0;
BA_ "GenSigSendType" SG_ 572 ONEBOX_7_RearWheelDirReq 0;
BA_ "GenSigSendType" SG_ 572 ONEBOX_7_iTASAvailable 0;
BA_ "GenSigSendType" SG_ 572 ONEBOX_7_iTASEnable 0;
BA_ "GenSigSendType" SG_ 572 ONEBOX_7_iTASBMsr_FA 0;
BA_ "GenSigSendType" SG_ 572 ONEBOX_7_iTASBMsr_RA 0;
BA_ "GenSigSendType" SG_ 572 ONEBOX_7_BSW_Active 0;
BA_ "GenSigSendType" SG_ 572 ONEBOX_7_iTASStuckDetected 0;
BA_ "GenSigSendType" SG_ 572 ONEBOX_7_iTASTDiscHigh 0;
BA_ "GenSigSendType" SG_ 572 ONEOBX_7_iTASAchMaxActTime 0;
BA_ "GenSigSendType" SG_ 572 ONEBOX_7_CRC2 0;
BA_ "GenSigSendType" SG_ 572 ONEBOX_7_RollgCntr2 0;
BA_ "GenSigSendType" SG_ 572 ONEBOX_7_Resd2 0;
BA_ "GenSigSendType" SG_ 572 ONEBOX_7_iTASTorqueInc_FA 0;
BA_ "GenSigSendType" SG_ 572 ONEBOX_7_DRIFTModeSts 0;
BA_ "GenSigSendType" SG_ 572 ONEBOX_7_DrivingMod 0;
BA_ "GenSigSendType" SG_ 572 ONEBOX_7_iTAS_Active 0;
BA_ "GenSigSendType" SG_ 572 ONEBOX_7_ExpertESPSts 0;
BA_ "GenSigSendType" SG_ 572 ONEBOX_7_Crossaxis_Active 0;
BA_ "GenSigSendType" SG_ 572 ONEBOX_7_iCCO_Active 0;
BA_ "GenSigStartValue" SG_ 572 ONEBOX_7_Crossaxis_TqtTrqReqVD 1;
BA_ "GenSigSendType" SG_ 572 ONEBOX_7_Crossaxis_TqtTrqReqVD 0;
BA_ "GenSigStartValue" SG_ 572 ONEBOX_7_iCCO_TqtTrqReqVD 1;
BA_ "GenSigSendType" SG_ 572 ONEBOX_7_iCCO_TqtTrqReqVD 0;
BA_ "GenSigSendType" SG_ 572 ONEBOX_7_iTASTorqueInc_RA 0;
BA_ "GenSigSendType" SG_ 572 ONEBOX_7_iCCO_TgtVel 0;
BA_ "GenSigSendType" SG_ 587 ONEBOX_4_CRC1 0;
BA_ "GenSigSendType" SG_ 587 ONEBOX_4_RollgCntr1 0;
BA_ "GenSigSendType" SG_ 587 ONEBOX_4_Resd1 0;
BA_ "GenSigInvalidValue" SG_ 587 ONEBOX_4_LHFWheelSpeedRPM 65535;
BA_ "ASIL" SG_ 587 ONEBOX_4_LHFWheelSpeedRPM 4;
BA_ "GenSigSendType" SG_ 587 ONEBOX_4_LHFWheelSpeedRPM 0;
BA_ "GenSigInvalidValue" SG_ 587 ONEBOX_4_RHFWheelSpeedRPM 65535;
BA_ "ASIL" SG_ 587 ONEBOX_4_RHFWheelSpeedRPM 4;
BA_ "GenSigSendType" SG_ 587 ONEBOX_4_RHFWheelSpeedRPM 0;
BA_ "GenSigSendType" SG_ 587 ONEBOX_4_CRC2 0;
BA_ "GenSigSendType" SG_ 587 ONEBOX_4_RollgCntr2 0;
BA_ "GenSigSendType" SG_ 587 ONEBOX_4_Resd2 0;
BA_ "ASIL" SG_ 587 LHRPulseCounter 2;
BA_ "GenSigSendType" SG_ 587 LHRPulseCounter 0;
BA_ "ASIL" SG_ 587 LHRPulseCounterFailSts 2;
BA_ "GenSigSendType" SG_ 587 LHRPulseCounterFailSts 0;
BA_ "ASIL" SG_ 587 RHRPulseCounter 2;
BA_ "GenSigSendType" SG_ 587 RHRPulseCounter 0;
BA_ "ASIL" SG_ 587 RHRPulseCounterFailSts 2;
BA_ "GenSigSendType" SG_ 587 RHRPulseCounterFailSts 0;
BA_ "GenSigSendType" SG_ 587 ONEBOX_4_CRC3 0;
BA_ "GenSigSendType" SG_ 587 ONEBOX_4_RollgCntr3 0;
BA_ "GenSigSendType" SG_ 587 ONEBOX_4_Resd3 0;
BA_ "ASIL" SG_ 587 RHFPulseCounter 2;
BA_ "GenSigSendType" SG_ 587 RHFPulseCounter 0;
BA_ "ASIL" SG_ 587 RHFPulseCounterFailSts 2;
BA_ "GenSigSendType" SG_ 587 RHFPulseCounterFailSts 0;
BA_ "ASIL" SG_ 587 LHFPulseCounter 2;
BA_ "GenSigSendType" SG_ 587 LHFPulseCounter 0;
BA_ "ASIL" SG_ 587 LHFPulseCounterFailSts 2;
BA_ "GenSigSendType" SG_ 587 LHFPulseCounterFailSts 0;
BA_ "ASIL" SG_ 587 LHFWheelSpeedRaw 2;
BA_ "GenSigSendType" SG_ 587 LHFWheelSpeedRaw 0;
BA_ "GenSigStartValue" SG_ 587 LHFWheelSpeedRawValidData 1;
BA_ "ASIL" SG_ 587 LHFWheelSpeedRawValidData 2;
BA_ "GenSigSendType" SG_ 587 LHFWheelSpeedRawValidData 0;
BA_ "GenSigSendType" SG_ 587 ONEBOX_4_CRC4 0;
BA_ "GenSigSendType" SG_ 587 ONEBOX_4_RollgCntr4 0;
BA_ "GenSigSendType" SG_ 587 ONEBOX_4_Resd4 0;
BA_ "ASIL" SG_ 587 RHFWheelSpeedRaw 2;
BA_ "GenSigSendType" SG_ 587 RHFWheelSpeedRaw 0;
BA_ "GenSigStartValue" SG_ 587 RHFWheelSpeedRawValidData 1;
BA_ "ASIL" SG_ 587 RHFWheelSpeedRawValidData 2;
BA_ "GenSigSendType" SG_ 587 RHFWheelSpeedRawValidData 0;
BA_ "ASIL" SG_ 587 LHRWheelSpeedRaw 2;
BA_ "GenSigSendType" SG_ 587 LHRWheelSpeedRaw 0;
BA_ "GenSigStartValue" SG_ 587 LHRWheelSpeedRawValidData 1;
BA_ "ASIL" SG_ 587 LHRWheelSpeedRawValidData 2;
BA_ "GenSigSendType" SG_ 587 LHRWheelSpeedRawValidData 0;
BA_ "ASIL" SG_ 587 RHRWheelSpeedRaw 2;
BA_ "GenSigSendType" SG_ 587 RHRWheelSpeedRaw 0;
BA_ "GenSigStartValue" SG_ 587 RHRWheelSpeedRawValidData 1;
BA_ "ASIL" SG_ 587 RHRWheelSpeedRawValidData 2;
BA_ "GenSigSendType" SG_ 587 RHRWheelSpeedRawValidData 0;
BA_ "GenSigSendType" SG_ 587 ONEBOX_4_CRC5 0;
BA_ "GenSigSendType" SG_ 587 ONEBOX_4_RollgCntr5 0;
BA_ "GenSigSendType" SG_ 587 ONEBOX_4_Resd5 0;
BA_ "GenSigSendType" SG_ 587 ONEBOX_4_CRC6 0;
BA_ "GenSigSendType" SG_ 587 ONEBOX_4_RollgCntr6 0;
BA_ "GenSigSendType" SG_ 587 ONEBOX_4_Resd6 0;
BA_ "GenSigSendType" SG_ 612 CRC1_264h 0;
BA_ "GenSigSendType" SG_ 612 RollgCntr1_264h 0;
BA_ "GenSigSendType" SG_ 612 ActrSt_264h 0;
BA_ "GenSigSendType" SG_ 612 RWUSt_264h 0;
BA_ "GenSigSendType" SG_ 612 IPB_EPBErrorStatus 0;
BA_ "GenSigSendType" SG_ 612 EPB_R_1_CRC2_264h 0;
BA_ "GenSigSendType" SG_ 612 EPB_R_1_RollgCntr2_264h 0;
BA_ "GenSigSendType" SG_ 612 EPB_R_1_Resd2_264h 0;
BA_ "GenSigSendType" SG_ 612 EPB_R_1_CRC3_264h 0;
BA_ "GenSigSendType" SG_ 612 EPB_R_1_RollgCntr3_264h 0;
BA_ "GenSigSendType" SG_ 612 EPB_R_1_Resd3_264h 0;
BA_ "GenSigStartValue" SG_ 631 CSA_2_AllWarningInfo 7;
BA_ "ASIL" SG_ 631 CSA_2_AllWarningInfo 2;
BA_ "GenSigSendType" SG_ 631 CSA_2_AllWarningInfo 0;
BA_ "GenSigSendType" SG_ 788 HighVoltageReq_314h 0;
BA_ "GenSigSendType" SG_ 794 FCM_2_Weather_signal_31Ah 0;
BA_ "GenSigSendType" SG_ 1041 ADS_CRC1_411h 0;
BA_ "GenSigSendType" SG_ 1041 ADS_RollgCntr1_411h 0;
BA_ "GenSigSendType" SG_ 1041 ADS_Resd1_411h 0;
BA_ "GenSigSendType" SG_ 1041 ADS_RadarWarning0Distance_411h 0;
BA_ "GenSigSendType" SG_ 1041 ADS_RadarWarning1Distance_411h 0;
BA_ "GenSigSendType" SG_ 1041 ADS_RadarWarning2Distance_411h 0;
BA_ "GenSigSendType" SG_ 1041 ADS_RadarWarning3Distance_411h 0;
BA_ "GenSigSendType" SG_ 1041 ADS_RadarWarning4Distance_411h 0;
BA_ "GenSigSendType" SG_ 1041 ADS_RadarWarning5Distance_411h 0;
BA_ "GenSigSendType" SG_ 1041 ADS_CRC2_411h 0;
BA_ "GenSigSendType" SG_ 1041 ADS_RollgCntr2_411h 0;
BA_ "GenSigSendType" SG_ 1041 ADS_Resd2_411h 0;
BA_ "GenSigSendType" SG_ 1041 ADS_RadarWarning6Distance_411h 0;
BA_ "GenSigSendType" SG_ 1041 ADS_RadarWarning7Distance_411h 0;
BA_ "GenSigSendType" SG_ 1041 ADS_RadarWarning8Distance_411h 0;
BA_ "GenSigSendType" SG_ 1041 ADS_RadarWarning9Distance_411h 0;
BA_ "GenSigSendType" SG_ 1041 ADS_RadarWarning10Distance_411h 0;
BA_ "GenSigSendType" SG_ 1041 ADS_RadarWarning11Distance_411h 0;
BA_ "GenSigSendType" SG_ 1041 ADS_CRC3_411h 0;
BA_ "GenSigSendType" SG_ 1041 ADS_RollgCntr3_411h 0;
BA_ "GenSigSendType" SG_ 1041 ADS_Resd3_411h 0;
BA_ "GenSigSendType" SG_ 1041 ADS_RadarWarning12Distance_411h 0;
BA_ "GenSigSendType" SG_ 1041 ADS_RadarWarning13Distance_411h 0;
BA_ "GenSigSendType" SG_ 1041 ADS_RadarWarning14Distance_411h 0;
BA_ "GenSigSendType" SG_ 1041 ADS_RadarWarning15Distance_411h 0;
BA_ "GenSigSendType" SG_ 1041 ADS_RadarWarning2AcLvl_411h 0;
BA_ "GenSigSendType" SG_ 1041 ADS_RadarWarning1AcLvl_411h 0;
BA_ "GenSigSendType" SG_ 1041 ADS_RadarWarning0AcLvl_411h 0;
BA_ "GenSigSendType" SG_ 1041 ADS_RadarWarning4AcLvl_411h 0;
BA_ "GenSigSendType" SG_ 1041 ADS_RadarWarning3AcLvl_411h 0;
BA_ "GenSigSendType" SG_ 1041 ADS_CRC4_411h 0;
BA_ "GenSigSendType" SG_ 1041 ADS_RollgCntr4_411h 0;
BA_ "GenSigSendType" SG_ 1041 ADS_Resd4_411h 0;
BA_ "GenSigSendType" SG_ 1041 ADS_RadarWarning7AcLvl_411h 0;
BA_ "GenSigSendType" SG_ 1041 ADS_RadarWarning6AcLvl_411h 0;
BA_ "GenSigSendType" SG_ 1041 ADS_RadarWarning5AcLvl_411h 0;
BA_ "GenSigSendType" SG_ 1041 ADS_RadarWarning10AcLvl_411h 0;
BA_ "GenSigSendType" SG_ 1041 ADS_RadarWarning9AcLvl_411h 0;
BA_ "GenSigSendType" SG_ 1041 ADS_RadarWarning8AcLvl_411h 0;
BA_ "GenSigSendType" SG_ 1041 ADS_RadarWarning12AcLvl_411h 0;
BA_ "GenSigSendType" SG_ 1041 ADS_RadarWarning11AcLvl_411h 0;
BA_ "GenSigSendType" SG_ 1041 ADS_RadarWarning15AcLvl_411h 0;
BA_ "GenSigSendType" SG_ 1041 ADS_RadarWarning14AcLvl_411h 0;
BA_ "GenSigSendType" SG_ 1041 ADS_RadarWarning13AcLvl_411h 0;
BA_ "GenSigSendType" SG_ 1041 ADC_MdcSentryAlarmMod_411h 0;
BA_ "GenSigSendType" SG_ 1041 ADC_FuncReq_SentryModDetec_411h 0;
BA_ "GenSigSendType" SG_ 1041 ADC_FuncReq_SentryModWarn_411h 0;
BA_ "GenSigSendType" SG_ 1041 ADS_CRC5_411h 0;
BA_ "GenSigSendType" SG_ 1041 ADS_RollgCntr5_411h 0;
BA_ "GenSigSendType" SG_ 1041 ADS_Resd5_411h 0;
BA_ "GenSigSendType" SG_ 1041 ADS_CRC6_411h 0;
BA_ "GenSigSendType" SG_ 1041 ADS_RollgCntr6_411h 0;
BA_ "GenSigSendType" SG_ 1041 ADS_Resd6_411h 0;
BA_ "GenSigSendType" SG_ 1042 ADS_CRC1_412h 0;
BA_ "GenSigSendType" SG_ 1042 ADS_RollgCntr1_412h 0;
BA_ "GenSigSendType" SG_ 1042 ADS_Resd1_412h 0;
BA_ "GenSigInvalidValue" SG_ 1042 ADS_MdcCrtSts_412h 7;
BA_ "GenSigSendType" SG_ 1042 ADS_MdcCrtSts_412h 0;
BA_ "GenSigSendType" SG_ 1042 ADS_CRC2_412h 0;
BA_ "GenSigSendType" SG_ 1042 ADS_RollgCntr2_412h 0;
BA_ "GenSigSendType" SG_ 1042 ADS_Resd2_412h 0;
BA_ "GenSigSendType" SG_ 1042 ADS_PwrOnOffReq_412h 0;
BA_ "GenSigSendType" SG_ 1042 ADS_ThmPostRun_412h 0;
BA_ "GenSigSendType" SG_ 1042 ADS_HVCtrlReq_412h 0;
BA_ "GenSigSendType" SG_ 1042 ADS_HiBeamReq_412h 0;
BA_ "GenSigSendType" SG_ 1042 ADS_HMAStatus_412h 0;
BA_ "GenSigSendType" SG_ 1042 ADS_hmaOnOffSts_412h 0;
BA_ "GenSigSendType" SG_ 1193 IPB_System_Status 0;
BA_ "GenSigSendType" SG_ 1204 VCU_1_G_CRC 0;
BA_ "GenSigSendType" SG_ 1204 VCU_1_G_RollgCntr 0;
BA_ "GenSigSendType" SG_ 1204 VCU_AcceleratorPosRawIVD 0;
BA_ "GenSigStartValue" SG_ 1204 VCU_1_G_Pwr 500;
BA_ "GenSigSendType" SG_ 1204 VCU_1_G_Pwr 0;
BA_ "ASIL" SG_ 1204 VCU_1_G_AcceleratorPosRaw 2;
BA_ "GenSigSendType" SG_ 1204 VCU_1_G_AcceleratorPosRaw 0;
BA_ "ASIL" SG_ 1204 VCU_1_G_PTReady 2;
BA_ "GenSigSendType" SG_ 1204 VCU_1_G_PTReady 0;
BA_ "GenSigStartValue" SG_ 1204 VCU_1_G_DriveMode 6;
BA_ "ASIL" SG_ 1204 VCU_1_G_DriveMode 2;
BA_ "GenSigSendType" SG_ 1204 VCU_1_G_DriveMode 0;
BA_ "GenSigSendType" SG_ 1204 VCU_1_G_BookChrgSetResponse 0;
BA_ "GenSigSendType" SG_ 1204 VCU_1_G_HvBattKeepWarmSts 0;
BA_ "GenSigSendType" SG_ 1204 VCU_1_G_HvBattKeepWarmActiveReq 0;
BA_ "GenSigInvalidValue" SG_ 1204 VCU_1_G_HundECAver 511;
BA_ "GenSigSendType" SG_ 1204 VCU_1_G_HundECAver 0;
BA_ "GenSigSendType" SG_ 1204 VCU_1_G_BookChrgSetStsFb 0;
BA_ "GenSigSendType" SG_ 1204 VCU_1_G_EgyRegenLevel 0;
BA_ "ASIL" SG_ 1204 VCU_1_G_PRNDGearAct 2;
BA_ "GenSigSendType" SG_ 1204 VCU_1_G_PRNDGearAct 0;
BA_ "GenSigSendType" SG_ 1209 VCU_2_G_CRC 0;
BA_ "GenSigSendType" SG_ 1209 VCU_2_G_RollgCntr 0;
BA_ "GenSigSendType" SG_ 1209 VCU_2_G_Resd 0;
BA_ "GenSigInvalidValue" SG_ 1209 VCU_2_G_GasPedalPosInvalidData 1;
BA_ "ASIL" SG_ 1209 VCU_2_G_GasPedalPosInvalidData 2;
BA_ "GenSigSendType" SG_ 1209 VCU_2_G_GasPedalPosInvalidData 0;
BA_ "ASIL" SG_ 1209 VCU_2_G_PowerLimit 2;
BA_ "GenSigSendType" SG_ 1209 VCU_2_G_PowerLimit 0;
BA_ "GenSigSendType" SG_ 1209 VCU_2_G_BrakeLightReq 0;
BA_ "ASIL" SG_ 1209 VCU_2_G_VehicleSystemFailure 2;
BA_ "GenSigSendType" SG_ 1209 VCU_2_G_VehicleSystemFailure 0;
BA_ "GenSigSendType" SG_ 1209 OnekeyHVOffSuccess_4B9h 0;
BA_ "GenSigSendType" SG_ 1209 VCU_2_G_BootloadSts 0;
BA_ "GenSigSendType" SG_ 1209 VCU_2_G_DischgSts 0;
BA_ "GenSigSendType" SG_ 1209 VCU_2_G_BrakePedalStsValidData 0;
BA_ "GenSigSendType" SG_ 1209 VCU_2_G_ExhibitionMod 0;
BA_ "ASIL" SG_ 1209 VCU_2_G_BrakePedalSts 2;
BA_ "GenSigSendType" SG_ 1209 VCU_2_G_BrakePedalSts 0;
BA_ "GenSigSendType" SG_ 1209 VCU_2_G_DCDCEnable 0;
BA_ "ASIL" SG_ 1209 VCU_2_G_HVReady 2;
BA_ "GenSigSendType" SG_ 1209 VCU_2_G_HVReady 0;
BA_ "GenSigSendType" SG_ 1209 Res_VCU_2_G_Brake_state 0;
BA_ "GenSigSendType" SG_ 1209 VCU_2_G_VCUEnergyflow 0;
BA_ "GenSigInvalidValue" SG_ 1209 VCU_2_G_GasPedalPosition 1023;
BA_ "ASIL" SG_ 1209 VCU_2_G_GasPedalPosition 2;
BA_ "GenSigSendType" SG_ 1209 VCU_2_G_GasPedalPosition 0;
BA_ "GenSigSendType" SG_ 1209 VCU_2_G_DrvGearShiftFailureIndcn 0;
BA_ "GenSigSendType" SG_ 1209 VCU_2_G_OnekeyHVoffStyle 0;
BA_ "GenSigSendType" SG_ 1212 VCU_3_G_CRC 0;
BA_ "GenSigSendType" SG_ 1212 VCU_3_G_RollgCntr 0;
BA_ "GenSigSendType" SG_ 1212 VCU_3_G_Resd 0;
BA_ "ASIL" SG_ 1212 VCU_3_G_ActWheelTorqueFA 2;
BA_ "GenSigSendType" SG_ 1212 VCU_3_G_ActWheelTorqueFA 0;
BA_ "ASIL" SG_ 1212 VCU_3_G_ActWheelTorqueRA 2;
BA_ "GenSigSendType" SG_ 1212 VCU_3_G_ActWheelTorqueRA 0;
BA_ "GenSigSendType" SG_ 1229 VCU_4_G_CRC 0;
BA_ "GenSigSendType" SG_ 1229 VCU_4_G_RollgCntr 0;
BA_ "GenSigSendType" SG_ 1229 VCU_4_G_Resd 0;
BA_ "GenSigInvalidValue" SG_ 1229 VCU_CLTC_RangeAval 1023;
BA_ "GenSigSendType" SG_ 1229 VCU_CLTC_RangeAval 0;
BA_ "GenSigInvalidValue" SG_ 1229 VCU_DynamicRangeAval 1023;
BA_ "GenSigSendType" SG_ 1229 VCU_DynamicRangeAval 0;
BA_ "GenSigInvalidValue" SG_ 1229 VCU_HighspdRangeAval 1023;
BA_ "GenSigSendType" SG_ 1229 VCU_HighspdRangeAval 0;
BA_ "GenSigInvalidValue" SG_ 1229 VCU_WLTC_RangeAval 1023;
BA_ "GenSigSendType" SG_ 1229 VCU_WLTC_RangeAval 0;
BA_ "GenSigSendType" SG_ 1235 EPS_2_CRC 0;
BA_ "GenSigSendType" SG_ 1235 EPS_2_RollgCntr 0;
BA_ "GenSigSendType" SG_ 1235 EPS_2_Resd 0;
BA_ "GenSigInvalidValue" SG_ 1235 EPS_Temp_monitor 255;
BA_ "GenSigStartValue" SG_ 1235 EPS_Temp_monitor 254;
BA_ "GenSigSendType" SG_ 1235 EPS_Temp_monitor 0;
BA_ "GenSigSendType" SG_ 1235 EPS_2_Steer_ReturnRmd 0;
BA_ "GenSigSendType" SG_ 1235 EPS_2_Steer_ReturnRmd_Sts 0;
BA_ "GenSigInvalidValue" SG_ 1235 EPS_AssistanceStyle_Sts 7;
BA_ "GenSigStartValue" SG_ 1235 EPS_AssistanceStyle_Sts 1;
BA_ "GenSigSendType" SG_ 1235 EPS_AssistanceStyle_Sts 0;
BA_ "GenSigSendType" SG_ 1235 EPS_2_MFS_ShakeSts 0;
BA_ "GenSigSendType" SG_ 1314 HCU_CRC1_522h 0;
BA_ "GenSigSendType" SG_ 1314 HCU_RollgCntr1_522h 0;
BA_ "GenSigSendType" SG_ 1314 HCU_Resd1_522h 0;
BA_ "GenSigSendType" SG_ 1314 HCU_V2lDisChgBck 0;
BA_ "GenSigSendType" SG_ 1314 HCU_DisChgMemFed 0;
BA_ "GenSigSendType" SG_ 1314 HCU_V2VDisChgBck 0;
BA_ "GenSigSendType" SG_ 1314 HCU_V2l_IntlDisChgBck 0;
BA_ "GenSigSendType" SG_ 1314 HCU_FuelDetnOpDefeated 0;
BA_ "GenSigInvalidValue" SG_ 1314 HCU_FuelDetnModSwtFed 3;
BA_ "GenSigSendType" SG_ 1314 HCU_FuelDetnModSwtFed 0;
BA_ "GenSigInvalidValue" SG_ 1314 HCU_FuelDetnStateFed 3;
BA_ "GenSigSendType" SG_ 1314 HCU_FuelDetnStateFed 0;
BA_ "GenSigInvalidValue" SG_ 1314 HCU_HVDownRepairModeFed 3;
BA_ "GenSigSendType" SG_ 1314 HCU_HVDownRepairModeFed 0;
BA_ "GenSigSendType" SG_ 1314 HCU_SumFuCns 0;
BA_ "GenSigInvalidValue" SG_ 1314 HCU_TrailerMode 3;
BA_ "GenSigSendType" SG_ 1314 HCU_TrailerMode 0;
BA_ "GenSigSendType" SG_ 1314 HCU_TABSwtFed_522h 0;
BA_ "GenSigSendType" SG_ 1314 HCU_MotSelfHeatLvlReq 0;
BA_ "GenSigSendType" SG_ 1314 HCU_MotSelfHeatEnReq 0;
BA_ "GenSigSendType" SG_ 1314 HCU_KeyDriveModememory 0;
BA_ "GenSigSendType" SG_ 1314 HCU_DrivePowerDispSetFed 0;
BA_ "GenSigSendType" SG_ 1314 HCU_TCMStsReq_522h 0;
BA_ "GenSigInvalidValue" SG_ 1314 HCU_EXPERTNormFed 3;
BA_ "GenSigSendType" SG_ 1314 HCU_EXPERTNormFed 0;
BA_ "GenSigSendType" SG_ 1314 HCU_4LModeFed 0;
BA_ "GenSigInvalidValue" SG_ 1314 HCU_EXPERTEcoFed 3;
BA_ "GenSigSendType" SG_ 1314 HCU_EXPERTEcoFed 0;
BA_ "GenSigSendType" SG_ 1314 HCU_SingleRegnRmn 0;
BA_ "GenSigSendType" SG_ 1314 HCU_DRIFTModeSts 0;
BA_ "GenSigSendType" SG_ 1314 HCU_CRC2_522h 0;
BA_ "GenSigSendType" SG_ 1314 HCU_RollgCntr2_522h 0;
BA_ "GenSigSendType" SG_ 1314 HCU_Resd2_522h 0;
BA_ "GenSigInvalidValue" SG_ 1314 HCU_EXPERTAWDFed 3;
BA_ "GenSigSendType" SG_ 1314 HCU_EXPERTAWDFed 0;
BA_ "GenSigInvalidValue" SG_ 1314 HCU_EXPERTRWDFed 3;
BA_ "GenSigSendType" SG_ 1314 HCU_EXPERTRWDFed 0;
BA_ "GenSigInvalidValue" SG_ 1314 HCU_CrossaxisFed 3;
BA_ "GenSigSendType" SG_ 1314 HCU_CrossaxisFed 0;
BA_ "GenSigInvalidValue" SG_ 1314 HCU_EXPERTSportFed 3;
BA_ "GenSigSendType" SG_ 1314 HCU_EXPERTSportFed 0;
BA_ "GenSigSendType" SG_ 1314 HCU_StopChrgnModeFed 0;
BA_ "GenSigInvalidValue" SG_ 1314 HCU_StopChrgnFed 3;
BA_ "GenSigSendType" SG_ 1314 HCU_StopChrgnFed 0;
BA_ "GenSigInvalidValue" SG_ 1314 HCU_CLIMBFed 3;
BA_ "GenSigSendType" SG_ 1314 HCU_CLIMBFed 0;
BA_ "GenSigInvalidValue" SG_ 1314 HCU_EXPERTAutoFed 3;
BA_ "GenSigSendType" SG_ 1314 HCU_EXPERTAutoFed 0;
BA_ "GenSigSendType" SG_ 1314 HCU_HEV_FunctionLimit 0;
BA_ "GenSigSendType" SG_ 1314 HCU_ParkingChargeReminder 0;
BA_ "GenSigSendType" SG_ 1314 HCU_PowerCut 0;
BA_ "GenSigSendType" SG_ 1314 HCU_IMMOReleaseSignal 0;
BA_ "GenSigSendType" SG_ 1314 HCU_LVPowSupSYSAbn_lit 0;
BA_ "GenSigSendType" SG_ 1314 HCU_ChrgnFctMemSt 0;
BA_ "GenSigSendType" SG_ 1314 HCU_PowerModeChangeInhibit 0;
BA_ "GenSigSendType" SG_ 1314 HCU_DisconnectChagWarn 0;
BA_ "GenSigSendType" SG_ 1314 HCU_EngineRunClmReq 0;
BA_ "GenSigSendType" SG_ 1314 HCU_VehicleSpeedMax_Limit 0;
BA_ "GenSigSendType" SG_ 1314 HCU_AccleAbility_Limit 0;
BA_ "GenSigSendType" SG_ 1314 HCU_DriveInhibit_GearP 0;
BA_ "GenSigSendType" SG_ 1314 HCU_SetModeNotChange 0;
BA_ "GenSigSendType" SG_ 1314 HCU_UTURNSnowFed 0;
BA_ "GenSigSendType" SG_ 1314 HCU_PowerLevel 0;
BA_ "GenSigSendType" SG_ 1314 HCU_TowingModeEna 0;
BA_ "GenSigSendType" SG_ 1314 HCU_LeaveVehicleWarning 0;
BA_ "GenSigSendType" SG_ 1314 HCU_DedicatedModeInhibit 0;
BA_ "GenSigSendType" SG_ 1314 HCU_DisChargeStopFault 0;
BA_ "GenSigSendType" SG_ 1314 HCU_RearEDLSts 0;
BA_ "GenSigSendType" SG_ 1314 HCU_FrntEDLSts 0;
BA_ "GenSigSendType" SG_ 1314 HCU_CRC3_522h 0;
BA_ "GenSigSendType" SG_ 1314 HCU_RollgCntr3_522h 0;
BA_ "GenSigSendType" SG_ 1314 HCU_Resd3_522h 0;
BA_ "GenSigSendType" SG_ 1314 HCU_CruiseLimitSpeedValue 0;
BA_ "GenSigSendType" SG_ 1314 HCU_DriveMode_JT 0;
BA_ "GenSigSendType" SG_ 1314 HCU_SocManageFed 0;
BA_ "GenSigSendType" SG_ 1314 HCU_SinglePedalMemFed 0;
BA_ "GenSigSendType" SG_ 1314 HCU_CCOSwtFed 0;
BA_ "GenSigStartValue" SG_ 1314 HCU_Pwr 2000;
BA_ "GenSigSendType" SG_ 1314 HCU_Pwr 0;
BA_ "GenSigSendType" SG_ 1314 HCU_DrvGearShiftFailureIndcn 0;
BA_ "GenSigSendType" SG_ 1314 HCU_UTURNSandFed 0;
BA_ "GenSigSendType" SG_ 1314 HCU_CruiseControlStatus 0;
BA_ "GenSigSendType" SG_ 1314 HCU_EXPERTEESPSet 0;
BA_ "GenSigSendType" SG_ 1314 HCU_EgyRegenLevel 0;
BA_ "GenSigSendType" SG_ 1314 HCU_CRC4_522h 0;
BA_ "GenSigSendType" SG_ 1314 HCU_RollgCntr4_522h 0;
BA_ "GenSigSendType" SG_ 1314 HCU_Resd4_522h 0;
BA_ "GenSigSendType" SG_ 1314 HCU_EngyFlowToDisp 0;
BA_ "GenSigSendType" SG_ 1314 HCU_UTURNGrassFed 0;
BA_ "GenSigSendType" SG_ 1314 HCU_UTURNMudFed 0;
BA_ "GenSigSendType" SG_ 1314 HCU_LTCDispFed 0;
BA_ "GenSigSendType" SG_ 1314 HCU_iTAS_Warn 0;
BA_ "GenSigSendType" SG_ 1314 HCU_iCCO_Warn 0;
BA_ "GenSigSendType" SG_ 1314 HCU_DriveModeChangeFail 0;
BA_ "GenSigSendType" SG_ 1314 HCU_25_Crossaxis_Warn 0;
BA_ "GenSigSendType" SG_ 1314 HCU_25_EDLFed 0;
BA_ "GenSigSendType" SG_ 1314 HCU_DraggingModeRemind 0;
BA_ "GenSigSendType" SG_ 1314 HCU_iTASSceneReq 0;
BA_ "GenSigSendType" SG_ 1314 HCU_25_iTAS_SlopWarn 0;
BA_ "GenSigSendType" SG_ 1314 HCU_ExterTempLowHint 0;
BA_ "GenSigSendType" SG_ 1314 HCU_iTAS_Active 0;
BA_ "GenSigSendType" SG_ 1314 HCU_25_VehSpdOffroadRmn 0;
BA_ "GenSigSendType" SG_ 1314 HCU_DrivingModReq 0;
BA_ "GenSigSendType" SG_ 1314 HCU_25_ADS_FctSts 0;
BA_ "GenSigSendType" SG_ 1314 HCU_25_DRIFTModeSetReq 0;
BA_ "GenSigSendType" SG_ 1314 HCU_25_CrossaxisReq 0;
BA_ "GenSigSendType" SG_ 1314 HCU_25_CCOSwtReq 0;
BA_ "GenSigSendType" SG_ 1314 HCU_CRC5_522h 0;
BA_ "GenSigSendType" SG_ 1314 HCU_RollgCntr5_522h 0;
BA_ "GenSigSendType" SG_ 1314 HCU_Resd5_522h 0;
BA_ "GenSigSendType" SG_ 1314 HCU_25_ErrorCode 0;
BA_ "GenSigSendType" SG_ 1314 HCU_25_ErrorCount 0;
BA_ "GenSigSendType" SG_ 1314 HCU_25_iDRIFT_Warn 0;
BA_ "GenSigSendType" SG_ 1314 HCU_25_SetVehSpdOffroad 0;
BA_ "GenSigSendType" SG_ 1314 HCU_25_LaunchMod_Warn 0;
BA_ "GenSigSendType" SG_ 1314 HCU_25_TAB_Warn 0;
BA_ "GenSigSendType" SG_ 1314 HCU_25_CCO_TextDisp 0;
BA_ "GenSigSendType" SG_ 1314 HCU_25_DCM_Warn 0;
BA_ "GenSigSendType" SG_ 1314 HCU_25_CCMFed 0;
BA_ "GenSigSendType" SG_ 1314 HCU_25_TABReq 0;
BA_ "GenSigInvalidValue" SG_ 1314 HCU_SumElecCns 4095;
BA_ "GenSigSendType" SG_ 1314 HCU_SumElecCns 0;
BA_ "GenSigSendType" SG_ 1314 HCU_CrossBorderSts 0;
BA_ "GenSigSendType" SG_ 1314 HCU_DischgSetSOCFed 0;
BA_ "GenSigSendType" SG_ 1314 HCU_facCleverDrvAct_522h 0;
BA_ "GenSigSendType" SG_ 1314 HCU_stCleverDrvAct_522h 0;
BA_ "GenSigSendType" SG_ 1314 HCU_stCleverRgnAct_522h 0;
BA_ "GenSigSendType" SG_ 1314 HCU_stCleverMainAct_522h 0;
BA_ "GenSigSendType" SG_ 1314 EnergySavingModeSts_522h 0;
BA_ "GenSigSendType" SG_ 1314 HCU_facCleverDrvActRstFed_522h 0;
BA_ "GenSigSendType" SG_ 1314 HCU_SailramainingT_Indc_522h 0;
BA_ "GenSigSendType" SG_ 1314 HCU_ATCM_Operation_REQ_522h 0;
BA_ "GenSigSendType" SG_ 1314 HCU_ModeSwFailureIndc_522h 0;
BA_ "GenSigSendType" SG_ 1314 HCU_Sailmode_522h 0;
BA_ "GenSigSendType" SG_ 1314 HCU_CarSickRelfModeFb 0;
BA_ "GenSigSendType" SG_ 1314 HCU_DeepSnowSts_522h 0;
BA_ "GenSigSendType" SG_ 1314 DriveModeChangeFailReason_522h 0;
BA_ "GenSigSendType" SG_ 1314 HCU_CLIMBDisReason_522h 0;
BA_ "GenSigSendType" SG_ 1314 HCU_CarSickRelfModeDisReason 0;
BA_ "GenSigSendType" SG_ 1314 HCU_DCMSwtFed 0;
BA_ "GenSigSendType" SG_ 1314 HCU_LightSandSts_522h 0;
BA_ "GenSigStartValue" SG_ 1582 srcNodeID_RMCU 46;
BA_ "GenSigSendType" SG_ 1582 srcNodeID_RMCU 0;
BA_ "GenSigSendType" SG_ 1582 RMR_RMCU 0;
BA_ "GenSigSendType" SG_ 1582 NMm_RMCU_Reserved1 0;
BA_ "GenSigSendType" SG_ 1582 RMCU_Wakeup_Poweron 0;
BA_ "GenSigSendType" SG_ 1582 RMCU_Wakeup_NM 0;
BA_ "GenSigSendType" SG_ 1582 RMCU_Wakeup_Diag 0;
BA_ "GenSigSendType" SG_ 1582 RMCU_Awake_Poweron 0;
BA_ "GenSigSendType" SG_ 1582 RMCU_Awake_NM 0;
BA_ "GenSigSendType" SG_ 1582 RMCU_Awake_Diag 0;
BA_ "GenSigSendType" SG_ 1582 RMCU_Awake_Discharge 0;
BA_ "GenSigSendType" SG_ 1582 RMCU_Awake_HVON 0;
VAL_ 555 ONEBOX_3_AVHSts 0 "Off" 1 "Standby" 2 "Active" 3 "Not used";
VAL_ 555 VehicleStandstill 0 "Not standstill" 1 "Standstill" 2 "invalid" 3 "Reserved";
VAL_ 555 NoBrakeForce 0 "Exist Brake Force" 1 "No Brake Force";
VAL_ 555 ONEBOX_3_AVHFailSts 0 "Not present" 1 "Fail present (lamp on)";
VAL_ 555 Reserved_EDCActive 0 "Not active" 1 "Active";
VAL_ 555 ECDTempOff 0 "not high" 1 "temp too high";
VAL_ 555 DCFail 0 "No error" 1 "Error";
VAL_ 555 CDDActive 0 "Not active" 1 "Active";
VAL_ 555 CDDAvailable 0 "Not available" 1 "Available";
VAL_ 555 Reserved_ESPLampInformation 0 "ESP Control Inactive" 1 "ESP Control Active";
VAL_ 555 ClutchOpenRequest 0 "Not Valid" 1 "Open Clutch Request" 2 "Torque max limt" 3 "Error";
VAL_ 555 QDCACC 0 "No error" 1 "Reversible error" 2 "Irreversible error" 3 "Not defined";
VAL_ 555 TorqueIncreaseReqRAValidData 0 "Not valid" 1 "Valid";
VAL_ 555 TorqueReductReqRAValidData 0 "Not valid" 1 "Valid";
VAL_ 555 TorqueIncreaseReqFAValidData 0 "Not valid" 1 "Valid";
VAL_ 555 TorqueReductReqFAFastValidData 0 "Not valid" 1 "Valid";
VAL_ 555 ESP_Park_CurrentSystemStatus 0 "Inhibit" 1 "Available" 2 "Active" 3 "Aborting" 4 "Reply for control" 5 "error" 6 "Reserved" 7 "Failure";
VAL_ 555 ESP_Pilot_CurrentSystemStatus 0 "Inhibit" 1 "Available" 2 "Active" 3 "Aborting" 4 "Reply for control" 5 "error" 6 "Reserved" 7 "Failure";
VAL_ 555 PlungerPressureValidData_22Bh 0 "Valid" 1 "Invalid";
VAL_ 555 IPB_InputRodStrokeStatus_22Bh 0 "Valid" 1 "Invalid";
VAL_ 555 SCMActive 0 "Not Active" 1 "Active";
VAL_ 555 SCMAvalable 0 "Not Available" 1 "Available";
VAL_ 555 BrakePedalPressStsValidData 0 "Valid" 1 "Invalid";
VAL_ 555 DTCActive 0 "Not Active" 1 "Active";
VAL_ 555 DTCAvailable 0 "Not Available" 1 "Available";
VAL_ 555 DTC_Intervention 0 "Not Active" 1 "Active";
VAL_ 555 BrakePedalPressSts 0 "Not Active" 1 "Not Pressed" 2 "Pressed" 3 "Error";
VAL_ 571 DrvDoorSts_23Bh 0 "Close" 1 "Ajar" 2 "full_open" 3 "Reserved";
VAL_ 571 DrvSeatBeltSW_23Bh 0 "Not Active" 1 "Active";
VAL_ 572 ONEBOX_7_TAB_Active 0 "Not Active" 1 "Active" 2 "Stand by" 3 "Failed";
VAL_ 572 ONEBOX_7_iTASDangerQuit 0 "No Active" 1 "Active";
VAL_ 572 ONEBOX_7_RearWheelDirReq 0 "Undefinable" 1 "Forward" 2 "Backward" 3 "Reserved";
VAL_ 572 ONEBOX_7_iTASAvailable 0 "Not available" 1 "Available";
VAL_ 572 ONEBOX_7_iTASEnable 0 "Not Enable" 1 "Enable";
VAL_ 572 ONEBOX_7_iTASBMsr_FA 0 "No Active" 1 "Active";
VAL_ 572 ONEBOX_7_iTASBMsr_RA 0 "No Active" 1 "Active";
VAL_ 572 ONEBOX_7_BSW_Active 0 "Not Active" 1 "Active" 2 "Filed" 3 "initialize";
VAL_ 572 ONEBOX_7_iTASStuckDetected 0 "No Active" 1 "Active";
VAL_ 572 ONEBOX_7_iTASTDiscHigh 0 "No Active" 1 "Active";
VAL_ 572 ONEOBX_7_iTASAchMaxActTime 0 "No Active" 1 "Active";
VAL_ 572 ONEBOX_7_DRIFTModeSts 0 "Not active" 1 "Entry Mode" 2 "Master mode" 3 "Expert mode";
VAL_ 572 ONEBOX_7_DrivingMod 0 "Normal" 1 "Snow" 2 "Mud" 3 "Sand" 4 "Rock" 5 "Wade" 6 "EXPERT" 7 "UTURN" 8 "DRIFT" 9 "OffroadRace" 10 "Reserved" 11 "Reserved" 12 "Reserved" 13 "Reserved" 14 "Reserved" 15 "Reserved";
VAL_ 572 ONEBOX_7_iTAS_Active 0 "Not Active" 1 "Standby" 2 "Active" 3 "Filed";
VAL_ 572 ONEBOX_7_ExpertESPSts 0 "ALL ON" 1 "TCS VDC OFF" 2 "ALL OFF" 3 "Reserved";
VAL_ 572 ONEBOX_7_Crossaxis_Active 0 "Not Active" 1 "Active" 2 "Filed" 3 "Reserved";
VAL_ 572 ONEBOX_7_iCCO_Active 0 "Not Active" 1 "Standby" 2 "Active" 3 "Filed";
VAL_ 572 ONEBOX_7_Crossaxis_TqtTrqReqVD 0 "Valid" 1 "Invalid";
VAL_ 572 ONEBOX_7_iCCO_TqtTrqReqVD 0 "Valid" 1 "Invalid";
VAL_ 587 LHRPulseCounterFailSts 0 "Fail Not Present" 1 "Fail Present";
VAL_ 587 RHRPulseCounterFailSts 0 "Fail Not Present" 1 "Fail Present";
VAL_ 587 RHFPulseCounterFailSts 0 "Fail Not Present" 1 "Fail Present";
VAL_ 587 LHFPulseCounterFailSts 0 "Fail Not Present" 1 "Fail Present";
VAL_ 587 LHFWheelSpeedRawValidData 0 "Valid" 1 "Not Valid";
VAL_ 587 RHFWheelSpeedRawValidData 0 "Valid" 1 "Not Valid";
VAL_ 587 LHRWheelSpeedRawValidData 0 "Valid" 1 "Not Valid";
VAL_ 587 RHRWheelSpeedRawValidData 0 "Valid" 1 "Not Valid";
VAL_ 612 ActrSt_264h 0 "Unknow" 1 "Applied" 2 "Released" 3 "Applying" 4 "Releasing" 5 "CompletelyReleased" 6 "Half Applied" 7 "Reserved";
VAL_ 612 RWUSt_264h 0 "No active" 1 "active";
VAL_ 612 IPB_EPBErrorStatus 0 "No_Error" 1 "Error";
VAL_ 631 CSA_2_AllWarningInfo 0 "No error" 1 "First grade failure of gear shift mechanism" 2 "Second grade failure of gear shift mechanism" 3 "Third grade failure of gear shift mechanism(Reserved)" 4 "Please check the position of the gear shift" 5 "Reserved" 6 "Reserved" 7 "Reserved";
VAL_ 788 HighVoltageReq_314h 0 "No_Active" 1 "Active";
VAL_ 794 FCM_2_Weather_signal_31Ah 0 "normal" 1 "Snow" 2 "Rain";
VAL_ 1041 ADS_RadarWarning2AcLvl_411h 0 "no request" 1 "Level 1" 2 "Level 2" 3 "Level 3" 4 "Level 4" 5 "Level 5" 7 "Invalid";
VAL_ 1041 ADS_RadarWarning1AcLvl_411h 0 "no request" 1 "Level 1" 2 "Level 2" 3 "Level 3" 4 "Level 4" 5 "Level 5" 7 "Invalid";
VAL_ 1041 ADS_RadarWarning0AcLvl_411h 0 "no request" 1 "Level 1" 2 "Level 2" 3 "Level 3" 4 "Level 4" 5 "Level 5" 7 "Invalid";
VAL_ 1041 ADS_RadarWarning4AcLvl_411h 0 "no request" 1 "Level 1" 2 "Level 2" 3 "Level 3" 4 "Level 4" 5 "Level 5" 7 "Invalid";
VAL_ 1041 ADS_RadarWarning3AcLvl_411h 0 "no request" 1 "Level 1" 2 "Level 2" 3 "Level 3" 4 "Level 4" 5 "Level 5" 7 "Invalid";
VAL_ 1041 ADS_RadarWarning7AcLvl_411h 0 "no request" 1 "Level 1" 2 "Level 2" 3 "Level 3" 4 "Level 4" 5 "Level 5" 7 "Invalid";
VAL_ 1041 ADS_RadarWarning6AcLvl_411h 0 "no request" 1 "Level 1" 2 "Level 2" 3 "Level 3" 4 "Level 4" 5 "Level 5" 7 "Invalid";
VAL_ 1041 ADS_RadarWarning5AcLvl_411h 0 "no request" 1 "Level 1" 2 "Level 2" 3 "Level 3" 4 "Level 4" 5 "Level 5" 7 "Invalid";
VAL_ 1041 ADS_RadarWarning10AcLvl_411h 0 "no request" 1 "Level 1" 2 "Level 2" 3 "Level 3" 4 "Level 4" 5 "Level 5" 7 "Invalid";
VAL_ 1041 ADS_RadarWarning9AcLvl_411h 0 "no request" 1 "Level 1" 2 "Level 2" 3 "Level 3" 4 "Level 4" 5 "Level 5" 7 "Invalid";
VAL_ 1041 ADS_RadarWarning8AcLvl_411h 0 "no request" 1 "Level 1" 2 "Level 2" 3 "Level 3" 4 "Level 4" 5 "Level 5" 7 "Invalid";
VAL_ 1041 ADS_RadarWarning12AcLvl_411h 0 "no request" 1 "Level 1" 2 "Level 2" 3 "Level 3" 4 "Level 4" 5 "Level 5" 7 "Invalid";
VAL_ 1041 ADS_RadarWarning11AcLvl_411h 0 "no request" 1 "Level 1" 2 "Level 2" 3 "Level 3" 4 "Level 4" 5 "Level 5" 7 "Invalid";
VAL_ 1041 ADS_RadarWarning15AcLvl_411h 0 "no request" 1 "Level 1" 2 "Level 2" 3 "Level 3" 4 "Level 4" 5 "Level 5" 7 "Invalid";
VAL_ 1041 ADS_RadarWarning14AcLvl_411h 0 "no request" 1 "Level 1" 2 "Level 2" 3 "Level 3" 4 "Level 4" 5 "Level 5" 7 "Invalid";
VAL_ 1041 ADS_RadarWarning13AcLvl_411h 0 "no request" 1 "Level 1" 2 "Level 2" 3 "Level 3" 4 "Level 4" 5 "Level 5" 7 "Invalid";
VAL_ 1041 ADC_MdcSentryAlarmMod_411h 0 "无告警" 1 "警报";
VAL_ 1041 ADC_FuncReq_SentryModDetec_411h 0 "OFF" 1 "哨兵模式维持";
VAL_ 1041 ADC_FuncReq_SentryModWarn_411h 0 "OFF" 1 "哨兵模式唤醒";
VAL_ 1042 ADS_MdcCrtSts_412h 0 "DeepSleep深度睡眠状态" 1 "LightSleep浅睡眠状态" 2 "Active激活状态" 3 "PartialActive半激活状态" 4 "Reserved" 5 "Reserved" 6 "Reserved" 7 "Invalid";
VAL_ 1042 ADS_PwrOnOffReq_412h 0 "no request" 1 "Power on 上电（从OFF至整车Ready状态）" 2 "Power off 下电（KL15 OFF)" 3 "上Ready（等同于过动力防盗）" 4 "下Ready（等同于退动力防盗，需维持高压）" 5 "reserved" 6 "reserved" 7 "reserved";
VAL_ 1042 ADS_ThmPostRun_412h 0 "No Request" 1 "Request";
VAL_ 1042 ADS_HVCtrlReq_412h 0 "No Request" 1 "Request";
VAL_ 1042 ADS_HiBeamReq_412h 0 "No Request" 1 "Request";
VAL_ 1042 ADS_HMAStatus_412h 0 "Off" 1 "Standby" 2 "Active" 3 "Failure";
VAL_ 1042 ADS_hmaOnOffSts_412h 0 "Initial" 1 "OFF" 2 "ON" 3 "INVALID";
VAL_ 1193 IPB_System_Status 0 "BBF_FullSys" 1 "BBF_DegradedPedalFeel" 2 "BBF_CircuitSperation" 3 "BBF_C1/2BoostOnly" 4 "HydBack w/ act / HydBack w/o act" 5 "reserved" 6 "reserved" 7 "reserved";
VAL_ 1204 VCU_AcceleratorPosRawIVD 0 "Valid" 1 "Invalid";
VAL_ 1204 VCU_1_G_PTReady 0 "LmpOFF" 1 "LmpON";
VAL_ 1204 VCU_1_G_DriveMode 0 "Not Active" 1 "ECO" 2 "Normal" 3 "Sport" 4 "Snow" 5 "Off Road" 6 "Individual" 7 "Reserved";
VAL_ 1204 VCU_1_G_BookChrgSetResponse 0 "Default" 1 "Success" 2 "Cancelled" 3 "Fail" 4 "Reserved";
VAL_ 1204 VCU_1_G_HvBattKeepWarmSts 0 "NotWarm" 1 "Warming" 2 "ExitWarm" 3 "WarmCompete" 4 "Reserved" 5 "Reserved" 6 "Reserved" 7 "Reserved";
VAL_ 1204 VCU_1_G_HvBattKeepWarmActiveReq 0 "default" 1 "StartWarm" 2 "EndWarm" 3 "Reserved";
VAL_ 1204 VCU_1_G_HundECAver 511 "Invalid";
VAL_ 1204 VCU_1_G_BookChrgSetStsFb 0 "NotBook" 1 "Booked" 2 "Reserved";
VAL_ 1204 VCU_1_G_EgyRegenLevel 0 "Off" 1 "Low" 2 "High" 3 "Reserved";
VAL_ 1204 VCU_1_G_PRNDGearAct 0 "Init" 1 "P" 2 "R" 3 "N" 4 "D" 5 "Reserved" 6 "Reserved" 7 "Reserved";
VAL_ 1209 VCU_2_G_GasPedalPosInvalidData 0 "Valid" 1 "Invalid";
VAL_ 1209 VCU_2_G_PowerLimit 0 "LmpOFF" 1 "LmpON";
VAL_ 1209 VCU_2_G_BrakeLightReq 0 "LmpOFF" 1 "LmpON";
VAL_ 1209 VCU_2_G_VehicleSystemFailure 0 "Fail not present" 1 "Fail present";
VAL_ 1209 OnekeyHVOffSuccess_4B9h 0 "Not Success" 1 "Success";
VAL_ 1209 VCU_2_G_BootloadSts 0 "No Display" 1 "Display";
VAL_ 1209 VCU_2_G_DischgSts 0 "No Active" 1 "Active";
VAL_ 1209 VCU_2_G_BrakePedalStsValidData 0 "Valid" 1 "Not Valid";
VAL_ 1209 VCU_2_G_ExhibitionMod 0 "No Active" 1 "Active";
VAL_ 1209 VCU_2_G_BrakePedalSts 0 "Not applied" 1 "Applied";
VAL_ 1209 VCU_2_G_DCDCEnable 0 "Disable" 1 "Enable";
VAL_ 1209 VCU_2_G_HVReady 0 "LmpOFF" 1 "LmpON";
VAL_ 1209 Res_VCU_2_G_Brake_state 0 "Not braking" 1 "Braking";
VAL_ 1209 VCU_2_G_VCUEnergyflow 0 "NotHvReady" 1 "charging" 2 "RWD" 3 "recycle" 4 "external_discharge" 5 "battery_heat" 6 "AWD" 7 "FWD" 8 "HV_ON" 9 "Reserved";
VAL_ 1209 VCU_2_G_GasPedalPosition 1023 "Invalid";
VAL_ 1209 VCU_2_G_DrvGearShiftFailureIndcn 0 "No Command" 1 "rake pedal applied" 2 "Over Speed" 3 "Charge Gun Connect" 4 "EPB Can Not Lock" 5 "EPB Can Not Release" 6 "Invalid shift" 7 "Shift fault";
VAL_ 1209 VCU_2_G_OnekeyHVoffStyle 0 "NotActive" 1 "Independent" 2 "Park Button";
VAL_ 1229 VCU_CLTC_RangeAval 1023 "Invalid";
VAL_ 1229 VCU_DynamicRangeAval 1023 "Invalid";
VAL_ 1229 VCU_HighspdRangeAval 1023 "Invalid";
VAL_ 1229 VCU_WLTC_RangeAval 1023 "Invalid";
VAL_ 1235 EPS_Temp_monitor 255 "Invalid";
VAL_ 1235 EPS_2_Steer_ReturnRmd 0 "No Tip" 1 "Tip return finish" 2 "Tip return left" 3 "Tip return right";
VAL_ 1235 EPS_2_Steer_ReturnRmd_Sts 0 "No_Active" 1 "ON" 2 "OFF" 3 "Reserved";
VAL_ 1235 EPS_AssistanceStyle_Sts 0 "Unavailable" 1 "Light" 2 "Midle" 3 "Heavy";
VAL_ 1235 EPS_2_MFS_ShakeSts 0 "No_Active" 1 "ON" 2 "OFF" 3 "reserved";
VAL_ 1314 HCU_V2lDisChgBck 0 "Not_Active" 1 "V2L_ON" 2 "OFF";
VAL_ 1314 HCU_DisChgMemFed 0 "Not_Active" 1 "Remember" 2 "No_Remember" 3 "Reserved";
VAL_ 1314 HCU_V2VDisChgBck 0 "Not_Active" 1 "V2V_ON" 2 "OFF";
VAL_ 1314 HCU_V2l_IntlDisChgBck 0 "Not_Active" 1 "V2L_ON" 2 "OFF";
VAL_ 1314 HCU_FuelDetnOpDefeated 0 "No_Prompt" 1 "Prompt";
VAL_ 1314 HCU_FuelDetnModSwtFed 0 "Not_Active" 1 "ON" 2 "OFF" 3 "Invalid";
VAL_ 1314 HCU_FuelDetnStateFed 0 "Not_Active" 1 "HighIdle" 2 "LowIdle" 3 "Invalid";
VAL_ 1314 HCU_HVDownRepairModeFed 0 "Not_Active" 1 "ON" 2 "OFF" 3 "Invalid";
VAL_ 1314 HCU_TrailerMode 0 "Not_Active" 1 "ON" 2 "OFF" 3 "Invalid";
VAL_ 1314 HCU_TABSwtFed_522h 0 "Not_Active" 1 "Active" 2 "Stand_by" 3 "Failed";
VAL_ 1314 HCU_MotSelfHeatLvlReq 0 "No Request" 1 "Level 1" 2 "Level 2" 3 "Level 3" 4 "Level 4" 5 "Level 5" 6 "Reserved" 7 "Reserved";
VAL_ 1314 HCU_MotSelfHeatEnReq 0 "Prohibit" 1 "Permission";
VAL_ 1314 HCU_KeyDriveModememory 0 "Not_Active" 1 "Remember" 2 "No_Remember";
VAL_ 1314 HCU_DrivePowerDispSetFed 0 "Not_Active" 1 "PercentDisp" 2 "kWDisp";
VAL_ 1314 HCU_TCMStsReq_522h 0 "Disable" 1 "Enable";
VAL_ 1314 HCU_EXPERTNormFed 0 "Not_Active" 1 "ON" 2 "OFF" 3 "Invalid";
VAL_ 1314 HCU_4LModeFed 0 "Not_Active" 1 "Active";
VAL_ 1314 HCU_EXPERTEcoFed 0 "Not_Active" 1 "ON" 2 "OFF" 3 "Invalid";
VAL_ 1314 HCU_SingleRegnRmn 0 "Not_Active" 1 "Active";
VAL_ 1314 HCU_DRIFTModeSts 0 "Not_Active" 1 "Entry_Mode" 2 "Master_mode" 3 "Expert_mode";
VAL_ 1314 HCU_EXPERTAWDFed 0 "Not_Active" 1 "ON" 2 "OFF" 3 "Invalid";
VAL_ 1314 HCU_EXPERTRWDFed 0 "Not_Active" 1 "ON" 2 "OFF" 3 "Invalid";
VAL_ 1314 HCU_CrossaxisFed 0 "Not_Active" 1 "Active" 2 "Stand_by" 3 "Failed";
VAL_ 1314 HCU_EXPERTSportFed 0 "Not_Active" 1 "ON" 2 "OFF" 3 "Invalid";
VAL_ 1314 HCU_StopChrgnModeFed 0 "Not_Active" 1 "Silence" 2 "Quick";
VAL_ 1314 HCU_StopChrgnFed 0 "Not_Active" 1 "ON" 2 "OFF" 3 "Invalid";
VAL_ 1314 HCU_CLIMBFed 0 "Not_Active" 1 "ON" 2 "OFF" 3 "InValid";
VAL_ 1314 HCU_EXPERTAutoFed 0 "Not_Active" 1 "ON" 2 "OFF" 3 "Invalid";
VAL_ 1314 HCU_HEV_FunctionLimit 0 "Not_Active" 1 "Active";
VAL_ 1314 HCU_ParkingChargeReminder 0 "Not_Active" 1 "Active";
VAL_ 1314 HCU_PowerCut 0 "Not_Active" 1 "Active";
VAL_ 1314 HCU_IMMOReleaseSignal 0 "Not_Active" 1 "Active";
VAL_ 1314 HCU_LVPowSupSYSAbn_lit 0 "Not_Active" 1 "Active";
VAL_ 1314 HCU_ChrgnFctMemSt 0 "Not_Active" 1 "Remember" 2 "No_Remember" 3 "Reserved";
VAL_ 1314 HCU_PowerModeChangeInhibit 0 "Not_Active" 1 "Active";
VAL_ 1314 HCU_DisconnectChagWarn 0 "Not_Active" 1 "Active";
VAL_ 1314 HCU_EngineRunClmReq 0 "Not_Active" 1 "Active";
VAL_ 1314 HCU_VehicleSpeedMax_Limit 0 "Not_Active" 1 "Active";
VAL_ 1314 HCU_AccleAbility_Limit 0 "Not_Active" 1 "Active";
VAL_ 1314 HCU_DriveInhibit_GearP 0 "Not_Active" 1 "Active";
VAL_ 1314 HCU_SetModeNotChange 0 "Not_Active" 1 "Active";
VAL_ 1314 HCU_UTURNSnowFed 0 "Not_Active" 1 "Active";
VAL_ 1314 HCU_PowerLevel 0 "Init" 1 "Level_1" 2 "Level_2" 3 "Level_3" 4 "Level_4";
VAL_ 1314 HCU_TowingModeEna 0 "No Prompt" 1 "Prompt";
VAL_ 1314 HCU_LeaveVehicleWarning 0 "Not_Active" 1 "Active";
VAL_ 1314 HCU_DedicatedModeInhibit 0 "Not_Active" 1 "Active";
VAL_ 1314 HCU_DisChargeStopFault 0 "Init" 1 "LowSOC" 2 "LowFuel";
VAL_ 1314 HCU_RearEDLSts 0 "No Lock" 1 "UNLock" 2 "Lock" 3 "Warning" 4 "UnAvailable" 5 "Stuck_Open" 6 "Stuck_Close" 7 "Reserved" 8 "Reserved" 9 "Reserved";
VAL_ 1314 HCU_FrntEDLSts 0 "No Lock" 1 "UNLock" 2 "Lock" 3 "Warning" 4 "UnAvailable" 5 "Stuck Open" 6 "Stuck Close" 7 "Rear4LReq" 8 "RearReq" 9 "4LReq";
VAL_ 1314 HCU_DriveMode_JT 0 "ECO" 1 "NORMAL" 2 "SPORT" 3 "SNOW" 4 "MUD" 5 "OffRoad" 6 "SAND" 7 "ROCK" 8 "EXPERT" 9 "X" 10 "WADE" 11 "UTURN" 12 "DRIFT" 13 "TOW" 14 "OffroadRace" 15 "CarSickRelfMode" 16 "CleverEngy" 17 "DCM";
VAL_ 1314 HCU_SocManageFed 0 "Default" 1 "Pure_electricity_priority_mode" 2 "Fuel_priority_mode" 3 "SOC_hold_mode" 4 "SAVE" 5 "Charge";
VAL_ 1314 HCU_SinglePedalMemFed 0 "ON" 1 "OFF";
VAL_ 1314 HCU_CCOSwtFed 0 "Not_Active" 1 "Active" 2 "Stand_by" 3 "Failed";
VAL_ 1314 HCU_DrvGearShiftFailureIndcn 0 "No_Command" 1 "brake_pedal_applied" 2 "Over_Speed" 3 "Charge_Gun_Connect" 4 "EPB_Can_Not_Lock" 5 "EPB_Can_Not_Release" 6 "Invalid_shift" 7 "Shift_fault" 8 "BrkPedl_to_start" 9 "OpenDoor_Shift";
VAL_ 1314 HCU_UTURNSandFed 0 "OFF" 1 "ON";
VAL_ 1314 HCU_CruiseControlStatus 0 "Not_Active" 1 "Active" 2 "Stand_by" 3 "Fault";
VAL_ 1314 HCU_EXPERTEESPSet 0 "ALLON" 1 "TCS_VDC_OFF" 2 "ALLOFF" 3 "Reserved";
VAL_ 1314 HCU_EgyRegenLevel 0 "Off" 1 "Low" 2 "High" 3 "middle" 4 "SinglePedl";
VAL_ 1314 HCU_EngyFlowToDisp 0 "Init" 1 "No_EngyFlow" 2 "Engine Idling" 3 "EV_FWD" 4 "EV_FWD_Regene" 5 "EV_RWD" 6 "EV_RWD_Regene" 7 "EV_4WD" 8 "EV_4WD_Regene" 9 "Series_FWD_BattChg" 10 "Series_FWD_BattDisChg" 11 "Series_FWD_BattNoCurr" 12 "Series_FWD_Regene" 13 "Series_RWD_BattChg" 14 "Series_RWD_BattDisChg" 15 "Series_RWD_BattNoCurr" 16 "Series_RWD_Regene" 17 "Series_4WD_BattChg" 18 "Series_4WD_BattDisChg" 19 "Series_4WD_BattNoCurr" 20 "Series_4WD_Regene" 21 "Parallel_FWD_BattChg" 22 "Parallel_FWD_BattDisChg" 23 "Parallel_FWD_BattNoCurr" 24 "Parallel_FWD_Regene" 25 "Parallel_4WD_BattChg" 26 "Parallel_4WD_BattDisChg" 27 "Parallel_4WD_BattNoCurr" 28 "Parallel_4WD_Regene" 29 "StopCharging_BatChg" 30 "StopCharging_BatDChg" 31 "StopCharging_BatNoCurr";
VAL_ 1314 HCU_UTURNGrassFed 0 "OFF" 1 "ON";
VAL_ 1314 HCU_UTURNMudFed 0 "OFF" 1 "ON";
VAL_ 1314 HCU_LTCDispFed 0 "Not Active" 1 "WLTC" 2 "CLTC";
VAL_ 1314 HCU_iTAS_Warn 0 "No_Warn" 1 "ELD Unable to lock" 2 "Please_Release_EPB" 3 "Please_slow_down" 4 "Disc temperature too high" 5 "vehicle is stuck" 6 "iTAS active max time" 7 "Please Open in D";
VAL_ 1314 HCU_iCCO_Warn 0 "No_Warn" 1 "Please_Release_EPB" 2 "Please_slow_down" 3 "Please_Close_ Door and Belt" 4 "Please_Open in D or N" 5 "Please_Close_APA/ACC/CC" 6 "Please_Exit_HDC/AVH" 7 "Please_Switch to Snow/Mud/Sand/Rock" 8 "Please Depress the brake pedal" 9 "iCCO Exited" 10 "Reserved" 11 "Reserved" 12 "Reserved" 13 "Reserved" 14 "Reserved" 15 "Reserved";
VAL_ 1314 HCU_DriveModeChangeFail 0 "NOT FAIL" 1 "FAIL";
VAL_ 1314 HCU_25_Crossaxis_Warn 0 "No_Warn" 1 "Please_Release_EPB" 2 "Crossaxis Exited" 3 "Please_Open in D" 4 "Please_Close_ Door and Belt" 5 "Please Depress the brake pedal" 6 "Not Adjust Suspension Height" 7 "Reserved";
VAL_ 1314 HCU_25_EDLFed 0 "Not_Active" 1 "Forward" 2 "Backward" 3 "Reserved";
VAL_ 1314 HCU_DraggingModeRemind 0 "Not_Active" 1 "Enter" 2 "Working" 3 "Exit" 4 "Reserved" 5 "Reserved" 6 "Reserved" 7 "Reserved";
VAL_ 1314 HCU_iTASSceneReq 0 "Not Active" 1 "Snow" 2 "Mud" 3 "Sand" 4 "Grass" 5 "Exit";
VAL_ 1314 HCU_25_iTAS_SlopWarn 0 "No_Warn" 1 "Active" 2 "Reserved" 3 "Reserved";
VAL_ 1314 HCU_ExterTempLowHint 0 "Init" 1 "Temp to HEV" 2 "Temp to EngRun" 3 "reserved";
VAL_ 1314 HCU_iTAS_Active 0 "Not_Active" 1 "Standby" 2 "Active" 3 "Filed";
VAL_ 1314 HCU_25_VehSpdOffroadRmn 0 "Not Acitve" 1 "Acitve";
VAL_ 1314 HCU_DrivingModReq 0 "Normal" 1 "Snow" 2 "Mud" 3 "Sand" 4 "Rock" 5 "Wade" 6 "Expert" 7 "UTURN" 8 "DRIFT" 9 "OffroadRace" 10 "DCM" 11 "Reserved" 12 "Reserved" 13 "Reserved" 14 "Reserved" 15 "Reserved" 16 "Reserved" 17 "Reserved" 18 "Reserved" 19 "Reserved" 20 "Reserved" 21 "Reserved" 22 "Reserved" 23 "Reserved" 24 "Reserved" 25 "Reserved" 26 "Reserved" 27 "Reserved" 28 "Reserved" 29 "Reserved" 30 "Reserved" 31 "invalid";
VAL_ 1314 HCU_25_ADS_FctSts 0 "Off" 1 "On";
VAL_ 1314 HCU_25_DRIFTModeSetReq 0 "Not Active" 1 "Entry Mode" 2 "Master mode" 3 "Expert mode";
VAL_ 1314 HCU_25_CrossaxisReq 0 "Not Active" 1 "ON" 2 "OFF" 3 "Not used";
VAL_ 1314 HCU_25_CCOSwtReq 0 "Not Active" 1 "ON" 2 "OFF" 3 "invalid";
VAL_ 1314 HCU_25_iDRIFT_Warn 0 "No_Warn" 1 "Please_Close_ Door and Belt" 2 "Please stop the vehicle" 3 "Error" 4 "Not Adjust Suspension Height";
VAL_ 1314 HCU_25_SetVehSpdOffroad 0 "No_Warn" 1 "Active" 2 "Reserved" 3 "Reserved";
VAL_ 1314 HCU_25_LaunchMod_Warn 0 "No_Warn" 1 "Active" 2 "Exit" 3 "Error" 4 "Reserved" 5 "Reserved" 6 "Reserved" 7 "Reserved";
VAL_ 1314 HCU_25_TAB_Warn 0 "No Warn" 1 "Please open CCO" 2 "Please Unlock EDL" 3 "Prohibit locking EDL" 4 "Reserved";
VAL_ 1314 HCU_25_CCO_TextDisp 0 "No_Warn" 1 "Please_Release_EPB" 2 "Please_Slow_Down" 3 "Please_Close_ Door and Belt" 4 "Please_Open in D" 5 "Please_Close_APA/ACC/CC" 6 "Please_Exit_HDC" 7 "Please_Switch to Mud/Sand/Rock" 8 "Reduce_Speed_Below 12kph" 9 "Please_Close_CCO" 10 "CC0 Exited";
VAL_ 1314 HCU_25_DCM_Warn 0 "No_Warn" 1 "Please_Release_EPB" 2 "Please_Close_ Door and Belt" 3 "Please_Open in D/R" 4 "Please_Close_APA/ACC/CC" 5 "Please_Exit_HDC" 6 "Please Depress the brake pedal" 7 "CCM Exited" 8 "Please enter or exit this mode when the vehicle is stationary" 9 "power limit" 10 "Please release the accelerator pedal" 11 "Please depress the brake pedal" 12 "Reserved" 13 "Reserved" 14 "Reserved" 15 "Reserved";
VAL_ 1314 HCU_25_CCMFed 0 "Not Active" 1 "On" 2 "Off" 3 "Reserved";
VAL_ 1314 HCU_25_TABReq 0 "Not Active" 1 "ON" 2 "OFF" 3 "Not used";
VAL_ 1314 HCU_CrossBorderSts 0 "Not Active" 1 "On" 2 "Off" 3 "Reserved";
VAL_ 1314 HCU_stCleverDrvAct_522h 0 "OFF" 1 "ON" 2 "Reserved" 3 "Invalid";
VAL_ 1314 HCU_stCleverRgnAct_522h 0 "OFF" 1 "ON" 2 "Reserved" 3 "Invalid";
VAL_ 1314 HCU_stCleverMainAct_522h 0 "OFF" 1 "ON" 2 "Reserved" 3 "Invalid";
VAL_ 1314 EnergySavingModeSts_522h 0 "Not Active" 1 "ON" 2 "OFF" 3 "Reserved";
VAL_ 1314 HCU_facCleverDrvActRstFed_522h 0 "Not Active" 1 "success" 2 "Fail" 3 "Reserved";
VAL_ 1314 HCU_ATCM_Operation_REQ_522h 0 "Not Active" 1 "Switch to sailfunc indiction" 2 "Switch to upbeach indiction" 3 "misoperation indiction”press sailfunc sw when conenmod “" 4 "misoperation indiction”press upbeach  sw when conenmod“" 5 "misoperation indiction”press upbeach sw when wadests“" 6 "reserved" 7 "reserved";
VAL_ 1314 HCU_ModeSwFailureIndc_522h 0 "Not Active" 1 "Entry navigation failed“Car door is not closed”" 2 "Entry navigation failed“Rearview mirror not deployed”" 3 "Entry navigation failed“Intake and exhaust waterproof valve malfunction”" 4 "Entry navigation failed“Speed too fast”" 5 "Entry navigation failed“Low battery”" 6 "Entry navigation failed“Air conditioning drain valve malfunction|Cooling fan malfunction”";
VAL_ 1314 HCU_Sailmode_522h 0 "Convenmod" 1 "SalWadeSts" 2 "DpWadeSts" 3 "SailingFunc" 4 "UpbeachSts" 5 "WaitfinspSts" 6 "EmerfloatingSts" 7 "Reserved";
VAL_ 1314 HCU_CarSickRelfModeFb 0 "NotActive" 1 "ON" 2 "OFF";
VAL_ 1314 HCU_DeepSnowSts_522h 0 "NOT ACTIVE" 1 "ON" 2 "OFF";
VAL_ 1314 DriveModeChangeFailReason_522h 0 "NOT FAIL" 1 "Fail" 2 "EngySavMod_Fail" 3 "Reserved";
VAL_ 1314 HCU_CLIMBDisReason_522h 0 "No_Warn" 1 "Please_brake_to_PtReady" 2 "Please_Open in D or N" 3 "Please_Switch to Rock" 4 "TCS/DTC/AVH/ABS_Active" 5 "Please_Close_APA/ACC/CC" 6 "Please_Slow_Down" 7 "Drive_System_Err" 8 "LongitudinalAcceleration_Invld" 9 "Pleased quit iCCO" 10 "OPD_Brake_not_Available" 11 "IPB_System_Err" 12 "Reserved" 13 "Reserved" 14 "Reserved" 15 "Reserved";
VAL_ 1314 HCU_CarSickRelfModeDisReason 0 "No prompts" 1 "Please exit off-road mode" 2 "Please exit CCO mode" 3 "Please exit power saving mode" 4 "Please exit Towing Mode" 5 "Please exit TrailerMode" 6 "Please exit CCMode" 7 "Please exit ADS mode";
VAL_ 1314 HCU_DCMSwtFed 0 "not active" 1 "sand" 2 "snow" 3 "crawl" 4 "forest" 5 "Tug of war" 6 "Rescue" 7 "Reserved";
VAL_ 1314 HCU_LightSandSts_522h 0 "Inactive" 1 "ON" 2 "OFF";
VAL_ 1582 RMR_RMCU 0 "Inactive" 1 "Active";
VAL_ 1582 RMCU_Wakeup_Poweron 0 "Inactive" 1 "Active";
VAL_ 1582 RMCU_Wakeup_NM 0 "Inactive" 1 "Active";
VAL_ 1582 RMCU_Wakeup_Diag 0 "Inactive" 1 "Active";
VAL_ 1582 RMCU_Awake_Poweron 0 "Inactive" 1 "Active";
VAL_ 1582 RMCU_Awake_NM 0 "Inactive" 1 "Active";
VAL_ 1582 RMCU_Awake_Diag 0 "Inactive" 1 "Active";
VAL_ 1582 RMCU_Awake_Discharge 0 "Inactive" 1 "Active";
VAL_ 1582 RMCU_Awake_HVON 0 "Inactive" 1 "Active";
